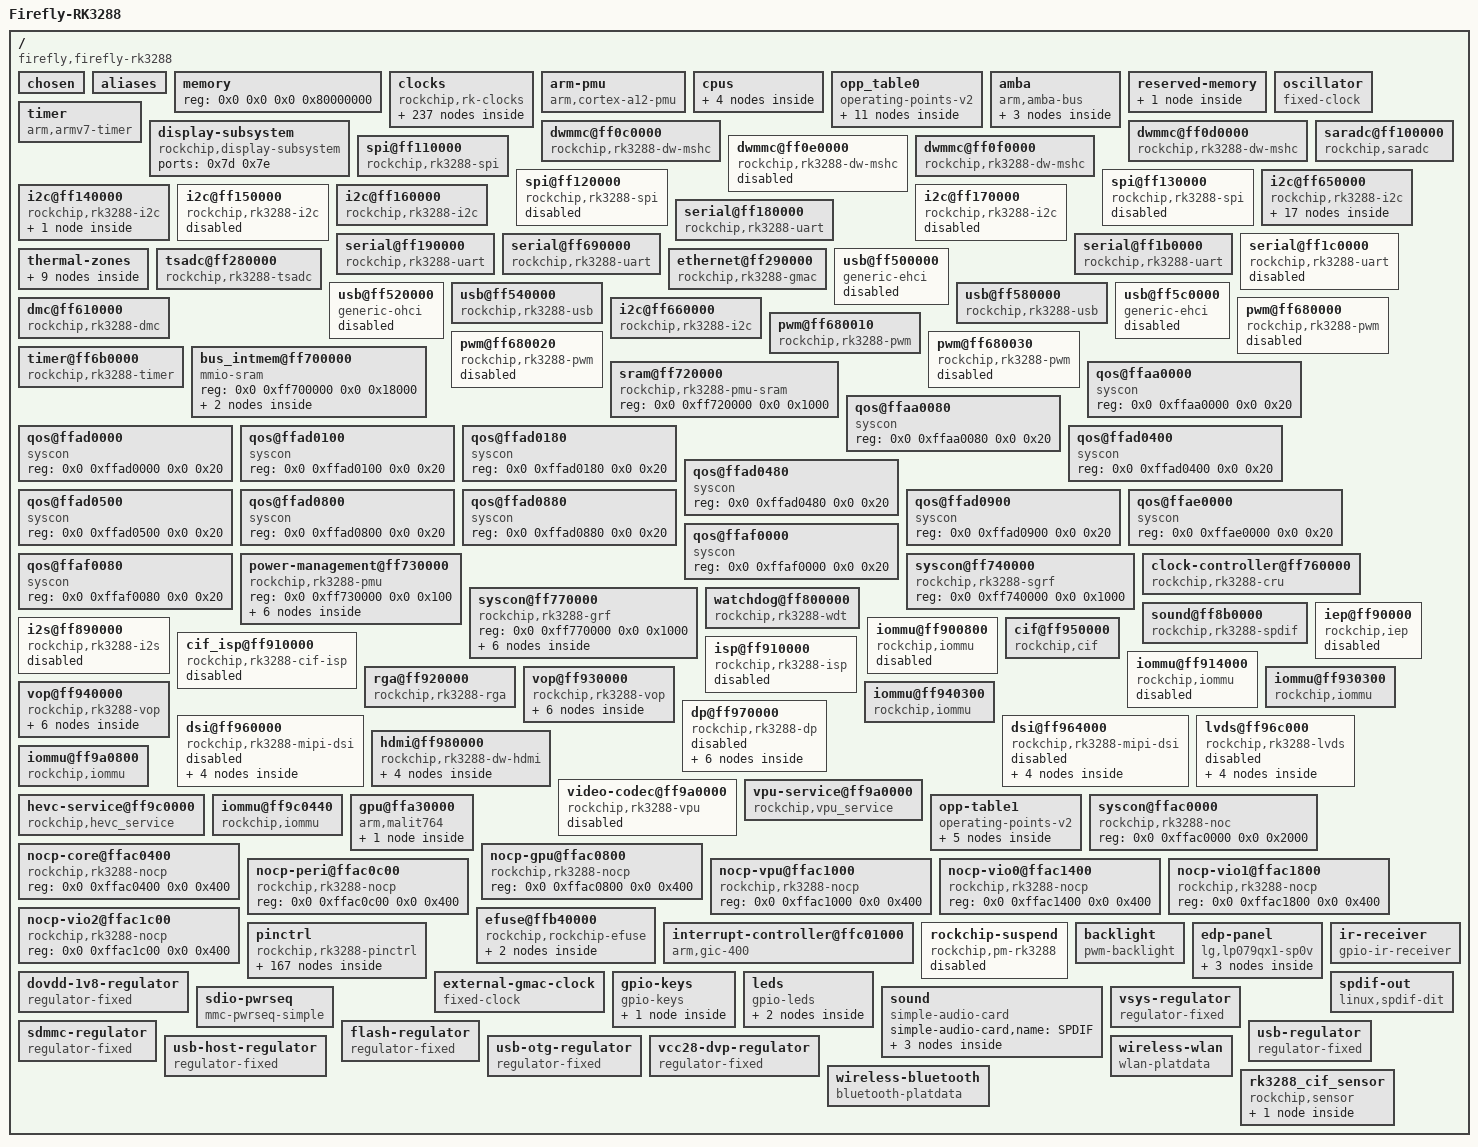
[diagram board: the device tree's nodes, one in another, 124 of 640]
/dts-v1/;

/ {
	#address-cells = <0x2>;
	#size-cells = <0x2>;
	compatible = "firefly,firefly-rk3288", "rockchip,rk3288";
	interrupt-parent = <0x1>;
	model = "Firefly-RK3288";

	chosen {
	};

	aliases {
		ethernet0 = "/ethernet@ff290000";
		i2c0 = "/i2c@ff650000";
		i2c1 = "/i2c@ff140000";
		i2c2 = "/i2c@ff660000";
		i2c3 = "/i2c@ff150000";
		i2c4 = "/i2c@ff160000";
		i2c5 = "/i2c@ff170000";
		mshc0 = "/dwmmc@ff0f0000";
		mshc1 = "/dwmmc@ff0c0000";
		mshc2 = "/dwmmc@ff0d0000";
		mshc3 = "/dwmmc@ff0e0000";
		serial0 = "/serial@ff180000";
		serial1 = "/serial@ff190000";
		serial2 = "/serial@ff690000";
		serial3 = "/serial@ff1b0000";
		serial4 = "/serial@ff1c0000";
		spi0 = "/spi@ff110000";
		spi1 = "/spi@ff120000";
		spi2 = "/spi@ff130000";
		dsi0 = "/dsi@ff960000";
		dsi1 = "/dsi@ff964000";
	};

	memory {
		device_type = "memory";
		reg = <0x0 0x0 0x0 0x80000000>;
	};

	clocks {
		compatible = "rockchip,rk-clocks";
		#address-cells = <0x1>;
		#size-cells = <0x1>;
		ranges = <0x0 0xff760000 0x1b0>;

		fixed_rate_cons {
			compatible = "rockchip,rk-fixed-rate-cons";

			xin12m {
				compatible = "rockchip,rk-fixed-clock";
				clocks = <0x2>;
				clock-output-names = "xin12m";
				clock-frequency = <0xb71b00>;
				#clock-cells = <0x0>;
				linux,phandle = <0x19>;
				phandle = <0x19>;
			};

			xin32k {
				compatible = "rockchip,rk-fixed-clock";
				clock-output-names = "xin32k";
				clock-frequency = <0x7d00>;
				#clock-cells = <0x0>;
				linux,phandle = <0x11>;
				phandle = <0x11>;
			};

			io_27m_in {
				compatible = "rockchip,rk-fixed-clock";
				clock-output-names = "io_27m_in";
				clock-frequency = <0x19bfcc0>;
				#clock-cells = <0x0>;
				linux,phandle = <0x4e>;
				phandle = <0x4e>;
			};

			dummy {
				compatible = "rockchip,rk-fixed-clock";
				clock-output-names = "dummy";
				clock-frequency = <0x0>;
				#clock-cells = <0x0>;
				linux,phandle = <0x12>;
				phandle = <0x12>;
			};

			dummy_cpll {
				compatible = "rockchip,rk-fixed-clock";
				clock-output-names = "dummy_cpll";
				clock-frequency = <0x0>;
				#clock-cells = <0x0>;
				linux,phandle = <0xf>;
				phandle = <0xf>;
			};

			i2s_clkin {
				compatible = "rockchip,rk-fixed-clock";
				clock-output-names = "i2s_clkin";
				clock-frequency = <0x0>;
				#clock-cells = <0x0>;
				linux,phandle = <0x18>;
				phandle = <0x18>;
			};

			edp_24m_clkin {
				compatible = "rockchip,rk-fixed-clock";
				#clock-cells = <0x0>;
				clock-output-names = "edp_24m_clkin";
				clock-frequency = <0x0>;
				linux,phandle = <0x41>;
				phandle = <0x41>;
			};

			gmac_clkin {
				compatible = "rockchip,rk-fixed-clock";
				#clock-cells = <0x0>;
				clock-output-names = "gmac_clkin";
				clock-frequency = <0x7735940>;
				linux,phandle = <0x33>;
				phandle = <0x33>;
			};

			clk_hsadc_ext {
				compatible = "rockchip,rk-fixed-clock";
				#clock-cells = <0x0>;
				clock-output-names = "clk_hsadc_ext";
				clock-frequency = <0x0>;
				linux,phandle = <0x35>;
				phandle = <0x35>;
			};

			jtag_clkin {
				compatible = "rockchip,rk-fixed-clock";
				#clock-cells = <0x0>;
				clock-output-names = "jtag_clkin";
				clock-frequency = <0x0>;
				linux,phandle = <0x61>;
				phandle = <0x61>;
			};

			pclkin_cif {
				compatible = "rockchip,rk-fixed-clock";
				#clock-cells = <0x0>;
				clock-output-names = "pclkin_cif";
				clock-frequency = <0x0>;
				linux,phandle = <0x72>;
				phandle = <0x72>;
			};

			pclkin_isp {
				compatible = "rockchip,rk-fixed-clock";
				#clock-cells = <0x0>;
				clock-output-names = "pclkin_isp";
				clock-frequency = <0x0>;
				linux,phandle = <0x73>;
				phandle = <0x73>;
			};

			hsadc_0_tsp {
				compatible = "rockchip,rk-fixed-clock";
				#clock-cells = <0x0>;
				clock-output-names = "hsadc_0_tsp";
				clock-frequency = <0x0>;
				linux,phandle = <0x65>;
				phandle = <0x65>;
			};

			hsadc_1_tsp {
				compatible = "rockchip,rk-fixed-clock";
				#clock-cells = <0x0>;
				clock-output-names = "hsadc_1_tsp";
				clock-frequency = <0x0>;
				linux,phandle = <0x66>;
				phandle = <0x66>;
			};
		};

		fixed_factor_cons {
			compatible = "rockchip,rk-fixed-factor-cons";

			otgphy0_480m {
				compatible = "rockchip,rk-fixed-factor-clock";
				clocks = <0x3 0x4>;
				clock-output-names = "otgphy0_480m";
				clock-div = <0x1>;
				clock-mult = <0x14>;
				#clock-cells = <0x0>;
				linux,phandle = <0x2a>;
				phandle = <0x2a>;
			};

			otgphy1_480m {
				compatible = "rockchip,rk-fixed-factor-clock";
				clocks = <0x3 0x5>;
				clock-output-names = "otgphy1_480m";
				clock-div = <0x1>;
				clock-mult = <0x14>;
				#clock-cells = <0x0>;
				linux,phandle = <0x28>;
				phandle = <0x28>;
			};

			otgphy2_480m {
				compatible = "rockchip,rk-fixed-factor-clock";
				clocks = <0x3 0x6>;
				clock-output-names = "otgphy2_480m";
				clock-div = <0x1>;
				clock-mult = <0x14>;
				#clock-cells = <0x0>;
				linux,phandle = <0x29>;
				phandle = <0x29>;
			};

			clk_hsadc_inv {
				compatible = "rockchip,rk-fixed-factor-clock";
				clocks = <0x4>;
				clock-output-names = "clk_hsadc_inv";
				clock-div = <0x1>;
				clock-mult = <0x1>;
				#clock-cells = <0x0>;
				linux,phandle = <0x36>;
				phandle = <0x36>;
			};

			pclkin_cif_inv {
				compatible = "rockchip,rk-fixed-factor-clock";
				clocks = <0x5 0x0>;
				clock-output-names = "pclkin_cif_inv";
				clock-div = <0x1>;
				clock-mult = <0x1>;
				#clock-cells = <0x0>;
				linux,phandle = <0x44>;
				phandle = <0x44>;
			};

			pclkin_isp_inv {
				compatible = "rockchip,rk-fixed-factor-clock";
				clocks = <0x5 0x3>;
				clock-output-names = "pclkin_isp_inv";
				clock-div = <0x1>;
				clock-mult = <0x1>;
				#clock-cells = <0x0>;
				linux,phandle = <0x43>;
				phandle = <0x43>;
			};

			hclk_vepu {
				compatible = "rockchip,rk-fixed-factor-clock";
				clocks = <0x6>;
				clock-output-names = "hclk_vepu";
				clock-div = <0x4>;
				clock-mult = <0x1>;
				#clock-cells = <0x0>;
			};

			hclk_vdpu {
				compatible = "rockchip,rk-fixed-factor-clock";
				clocks = <0x7>;
				clock-output-names = "hclk_vdpu";
				clock-div = <0x4>;
				clock-mult = <0x1>;
				#clock-cells = <0x0>;
			};
		};

		pd_cons {
			compatible = "rockchip,rk-pd-cons";

			pd_gpu {
				compatible = "rockchip,rk-pd-clock";
				clock-output-names = "pd_gpu";
				rockchip,pd-id = <0x8>;
				#clock-cells = <0x0>;
			};

			pd_video {
				compatible = "rockchip,rk-pd-clock";
				clock-output-names = "pd_video";
				rockchip,pd-id = <0xc>;
				#clock-cells = <0x0>;
			};

			pd_vio {
				compatible = "rockchip,rk-pd-clock";
				clock-output-names = "pd_vio";
				rockchip,pd-id = <0xd>;
				#clock-cells = <0x0>;
				linux,phandle = <0x8>;
				phandle = <0x8>;
			};

			pd_hevc {
				compatible = "rockchip,rk-pd-clock";
				clock-output-names = "pd_hevc";
				rockchip,pd-id = <0x9>;
				#clock-cells = <0x0>;
			};

			pd_edp {
				compatible = "rockchip,rk-pd-clock";
				clocks = <0x8>;
				clock-output-names = "pd_edp";
				rockchip,pd-id = <0xff>;
				#clock-cells = <0x0>;
			};

			pd_vop0 {
				compatible = "rockchip,rk-pd-clock";
				clocks = <0x8>;
				clock-output-names = "pd_vop0";
				rockchip,pd-id = <0xff>;
				#clock-cells = <0x0>;
			};

			pd_vop1 {
				compatible = "rockchip,rk-pd-clock";
				clocks = <0x8>;
				clock-output-names = "pd_vop1";
				rockchip,pd-id = <0xff>;
				#clock-cells = <0x0>;
			};

			pd_isp {
				compatible = "rockchip,rk-pd-clock";
				clocks = <0x8>;
				clock-output-names = "pd_isp";
				rockchip,pd-id = <0xff>;
				#clock-cells = <0x0>;
				linux,phandle = <0xdf>;
				phandle = <0xdf>;
			};

			pd_iep {
				compatible = "rockchip,rk-pd-clock";
				clocks = <0x8>;
				clock-output-names = "pd_iep";
				rockchip,pd-id = <0xff>;
				#clock-cells = <0x0>;
			};

			pd_rga {
				compatible = "rockchip,rk-pd-clock";
				clocks = <0x8>;
				clock-output-names = "pd_rga";
				rockchip,pd-id = <0xff>;
				#clock-cells = <0x0>;
			};

			pd_mipicsi {
				compatible = "rockchip,rk-pd-clock";
				clocks = <0x8>;
				clock-output-names = "pd_mipicsi";
				rockchip,pd-id = <0xff>;
				#clock-cells = <0x0>;
			};

			pd_mipidsi {
				compatible = "rockchip,rk-pd-clock";
				clocks = <0x8>;
				clock-output-names = "pd_mipidsi";
				rockchip,pd-id = <0xff>;
				#clock-cells = <0x0>;
			};

			pd_lvds {
				compatible = "rockchip,rk-pd-clock";
				clocks = <0x8>;
				clock-output-names = "pd_lvds";
				rockchip,pd-id = <0xff>;
				#clock-cells = <0x0>;
			};

			pd_hdmi {
				compatible = "rockchip,rk-pd-clock";
				clocks = <0x8>;
				clock-output-names = "pd_hdmi";
				rockchip,pd-id = <0xff>;
				#clock-cells = <0x0>;
			};
		};

		clock_regs {
			compatible = "rockchip,rk-clock-regs";
			#address-cells = <0x1>;
			#size-cells = <0x1>;
			reg = <0x0 0x3ff>;
			ranges;

			pll_cons {
				compatible = "rockchip,rk-pll-cons";
				#address-cells = <0x1>;
				#size-cells = <0x1>;
				ranges;

				pll-clk@0000 {
					compatible = "rockchip,rk3188-pll-clk";
					reg = <0x0 0x10>;
					mode-reg = <0x50 0x0>;
					status-reg = <0x284 0x6>;
					clocks = <0x2>;
					clock-output-names = "clk_apll";
					rockchip,pll-type = <0x10>;
					#clock-cells = <0x0>;
					linux,phandle = <0xa>;
					phandle = <0xa>;
				};

				pll-clk@0010 {
					compatible = "rockchip,rk3188-pll-clk";
					reg = <0x10 0x10>;
					mode-reg = <0x50 0x4>;
					status-reg = <0x284 0x5>;
					clocks = <0x2>;
					clock-output-names = "clk_dpll";
					rockchip,pll-type = <0x4>;
					#clock-cells = <0x0>;
					linux,phandle = <0x3a>;
					phandle = <0x3a>;
				};

				pll-clk@0020 {
					compatible = "rockchip,rk3188-pll-clk";
					reg = <0x20 0x10>;
					mode-reg = <0x50 0x8>;
					status-reg = <0x284 0x7>;
					clocks = <0x2>;
					clock-output-names = "clk_cpll";
					rockchip,pll-type = <0x20>;
					#clock-cells = <0x0>;
					#clock-init-cells = <0x1>;
					linux,phandle = <0x3d>;
					phandle = <0x3d>;
				};

				pll-clk@0030 {
					compatible = "rockchip,rk3188-pll-clk";
					reg = <0x30 0x10>;
					mode-reg = <0x50 0xc>;
					status-reg = <0x284 0x8>;
					clocks = <0x2>;
					clock-output-names = "clk_gpll";
					rockchip,pll-type = <0x4>;
					#clock-cells = <0x0>;
					#clock-init-cells = <0x1>;
					linux,phandle = <0x10>;
					phandle = <0x10>;
				};

				pll-clk@0040 {
					compatible = "rockchip,rk3188-pll-clk";
					reg = <0x40 0x10>;
					mode-reg = <0x50 0xe>;
					status-reg = <0x284 0x9>;
					clocks = <0x2>;
					clock-output-names = "clk_npll";
					rockchip,pll-type = <0x4>;
					#clock-cells = <0x0>;
					#clock-init-cells = <0x1>;
					linux,phandle = <0x1f>;
					phandle = <0x1f>;
				};
			};

			clk_sel_cons {
				compatible = "rockchip,rk-sel-cons";
				#address-cells = <0x1>;
				#size-cells = <0x1>;
				ranges;

				sel-con@0060 {
					compatible = "rockchip,rk3188-selcon";
					reg = <0x60 0x4>;
					#address-cells = <0x1>;
					#size-cells = <0x1>;

					aclk_core_m0_div {
						compatible = "rockchip,rk3188-div-con";
						rockchip,bits = <0x0 0x4>;
						clocks = <0x9>;
						clock-output-names = "aclk_core_m0";
						rockchip,div-type = <0x0>;
						#clock-cells = <0x0>;
						rockchip,clkops-idx = <0xc>;
						linux,phandle = <0x6c>;
						phandle = <0x6c>;
					};

					aclk_core_mp_div {
						compatible = "rockchip,rk3188-div-con";
						rockchip,bits = <0x4 0x4>;
						clocks = <0x9>;
						clock-output-names = "aclk_core_mp";
						rockchip,div-type = <0x0>;
						#clock-cells = <0x0>;
						rockchip,clkops-idx = <0xc>;
						linux,phandle = <0x6d>;
						phandle = <0x6d>;
					};

					clk_core_div {
						compatible = "rockchip,rk3188-div-con";
						rockchip,bits = <0x8 0x5>;
						clocks = <0x9>;
						clock-output-names = "clk_core";
						rockchip,div-type = <0x0>;
						#clock-cells = <0x0>;
						rockchip,clkops-idx = <0xb>;
						rockchip,flags = <0xc0>;
					};

					clk_core_mux {
						compatible = "rockchip,rk3188-mux-con";
						rockchip,bits = <0xf 0x1>;
						clocks = <0xa 0xb 0x2>;
						clock-output-names = "clk_core";
						#clock-cells = <0x0>;
						#clock-init-cells = <0x1>;
						linux,phandle = <0x9>;
						phandle = <0x9>;
					};
				};

				sel-con@0064 {
					compatible = "rockchip,rk3188-selcon";
					reg = <0x64 0x4>;
					#address-cells = <0x1>;
					#size-cells = <0x1>;

					aclk_bus_div {
						compatible = "rockchip,rk3188-div-con";
						rockchip,bits = <0x0 0x3>;
						clocks = <0xc>;
						clock-output-names = "aclk_bus";
						rockchip,div-type = <0x0>;
						#clock-cells = <0x0>;
						#clock-init-cells = <0x1>;
						linux,phandle = <0xe>;
						phandle = <0xe>;
					};

					aclk_bus_src_div {
						compatible = "rockchip,rk3188-div-con";
						rockchip,bits = <0x3 0x5>;
						clocks = <0xd>;
						clock-output-names = "aclk_bus_src";
						rockchip,div-type = <0x0>;
						#clock-cells = <0x0>;
						rockchip,clkops-idx = <0x1>;
						rockchip,flags = <0x80>;
						linux,phandle = <0xc>;
						phandle = <0xc>;
					};

					hclk_bus_div {
						compatible = "rockchip,rk3188-div-con";
						rockchip,bits = <0x8 0x2>;
						clocks = <0xe>;
						clock-output-names = "hclk_bus";
						rockchip,div-type = <0x80>;
						rockchip,div-relations = <0x0 0x1 0x1 0x2 0x3 0x4>;
						#clock-cells = <0x0>;
						#clock-init-cells = <0x1>;
						linux,phandle = <0x57>;
						phandle = <0x57>;
					};

					pclk_bus_div {
						compatible = "rockchip,rk3188-div-con";
						rockchip,bits = <0xc 0x3>;
						clocks = <0xe>;
						clock-output-names = "pclk_bus";
						rockchip,div-type = <0x0>;
						#clock-cells = <0x0>;
						#clock-init-cells = <0x1>;
						linux,phandle = <0x58>;
						phandle = <0x58>;
					};

					aclk_bus_src_mux {
						compatible = "rockchip,rk3188-mux-con";
						rockchip,bits = <0xf 0x1>;
						clocks = <0xf 0x10>;
						clock-output-names = "aclk_bus_src";
						#clock-cells = <0x0>;
						#clock-init-cells = <0x1>;
						linux,phandle = <0xd>;
						phandle = <0xd>;
					};
				};

				sel-con@0068 {
					compatible = "rockchip,rk3188-selcon";
					reg = <0x68 0x4>;
					#address-cells = <0x1>;
					#size-cells = <0x1>;

					clk_tsadc_div {
						compatible = "rockchip,rk3188-div-con";
						rockchip,bits = <0x0 0x6>;
						clocks = <0x11>;
						clock-output-names = "clk_tsadc";
						rockchip,div-type = <0x0>;
						#clock-cells = <0x0>;
						linux,phandle = <0x5b>;
						phandle = <0x5b>;
					};

					testout_div {
						compatible = "rockchip,rk3188-div-con";
						rockchip,bits = <0x8 0x5>;
						clocks = <0x12>;
						clock-output-names = "testout_div";
						rockchip,div-type = <0x0>;
						#clock-cells = <0x0>;
					};
				};

				sel-con@006c {
					compatible = "rockchip,rk3188-selcon";
					reg = <0x6c 0x4>;
					#address-cells = <0x1>;
					#size-cells = <0x1>;

					clk_uart4_div {
						compatible = "rockchip,rk3188-div-con";
						rockchip,bits = <0x0 0x7>;
						clocks = <0x13>;
						clock-output-names = "clk_uart4_div";
						rockchip,div-type = <0x0>;
						#clock-cells = <0x0>;
						linux,phandle = <0x14>;
						phandle = <0x14>;
					};

					uart4_mux {
						compatible = "rockchip,rk3188-mux-con";
						rockchip,bits = <0x8 0x2>;
						clocks = <0x14 0x15 0x2 0x12>;
						clock-output-names = "clk_uart4";
						#clock-cells = <0x0>;
						rockchip,clkops-idx = <0xe>;
						rockchip,flags = <0x4>;
					};
				};

				sel-con@0070 {
					compatible = "rockchip,rk3188-selcon";
					reg = <0x70 0x4>;
					#address-cells = <0x1>;
					#size-cells = <0x1>;

					i2s_pll_div {
						compatible = "rockchip,rk3188-div-con";
						rockchip,bits = <0x0 0x7>;
						clocks = <0x16>;
						clock-output-names = "clk_i2s_pll";
						rockchip,div-type = <0x0>;
						#clock-cells = <0x0>;
						rockchip,clkops-idx = <0x1>;
						rockchip,flags = <0x80>;
					};

					i2s_mux {
						compatible = "rockchip,rk3188-mux-con";
						rockchip,bits = <0x8 0x2>;
						clocks = <0x16 0x17 0x18 0x19>;
						clock-output-names = "clk_i2s";
						#clock-cells = <0x0>;
						rockchip,clkops-idx = <0xe>;
						rockchip,flags = <0x4>;
						linux,phandle = <0x1a>;
						phandle = <0x1a>;
					};

					i2s_outclk_mux {
						compatible = "rockchip,rk3188-mux-con";
						rockchip,bits = <0xc 0x1>;
						clocks = <0x1a 0x19>;
						clock-output-names = "clk_i2s_out";
						#clock-cells = <0x0>;
						linux,phandle = <0x5e>;
						phandle = <0x5e>;
					};

					i2s_pll_mux {
						compatible = "rockchip,rk3188-mux-con";
						rockchip,bits = <0xf 0x1>;
						clocks = <0xf 0x10>;
						clock-output-names = "clk_i2s_pll";
						#clock-cells = <0x0>;
						#clock-init-cells = <0x1>;
						linux,phandle = <0x16>;
						phandle = <0x16>;
					};
				};

				sel-con@0074 {
					compatible = "rockchip,rk3188-selcon";
					reg = <0x74 0x4>;
					#address-cells = <0x1>;
					#size-cells = <0x1>;

					spdif_div {
						compatible = "rockchip,rk3188-div-con";
						rockchip,bits = <0x0 0x7>;
						clocks = <0x1b>;
						clock-output-names = "spdif_div";
						rockchip,div-type = <0x0>;
						#clock-cells = <0x0>;
						linux,phandle = <0x1c>;
						phandle = <0x1c>;
					};

					spdif_mux {
						compatible = "rockchip,rk3188-mux-con";
						rockchip,bits = <0x8 0x2>;
						clocks = <0x1c 0x1d 0x19 0x12>;
						clock-output-names = "clk_spdif";
						#clock-cells = <0x0>;
						rockchip,clkops-idx = <0xe>;
						rockchip,flags = <0x4>;
						linux,phandle = <0x5f>;
						phandle = <0x5f>;
					};

					spdif_pll_mux {
						compatible = "rockchip,rk3188-mux-con";
						rockchip,bits = <0xf 0x1>;
						clocks = <0xf 0x10>;
						clock-output-names = "clk_spdif_pll";
						#clock-cells = <0x0>;
						#clock-init-cells = <0x1>;
						linux,phandle = <0x1b>;
						phandle = <0x1b>;
					};
				};

				sel-con@0078 {
					compatible = "rockchip,rk3188-selcon";
					reg = <0x78 0x4>;
					#address-cells = <0x1>;
					#size-cells = <0x1>;

					clk_isp_div {
						compatible = "rockchip,rk3188-div-con";
						rockchip,bits = <0x0 0x6>;
						clocks = <0x1e>;
						clock-output-names = "clk_isp";
						rockchip,div-type = <0x0>;
						#clock-cells = <0x0>;
						rockchip,clkops-idx = <0x1>;
					};

					clk_isp_mux {
						compatible = "rockchip,rk3188-mux-con";
						rockchip,bits = <0x6 0x2>;
						clocks = <0xf 0x10 0x1f>;
						clock-output-names = "clk_isp";
						#clock-cells = <0x0>;
						#clock-init-cells = <0x1>;
						linux,phandle = <0x1e>;
						phandle = <0x1e>;
					};

					clk_isp_jpe_div {
						compatible = "rockchip,rk3188-div-con";
						rockchip,bits = <0x8 0x6>;
						clocks = <0x20>;
						clock-output-names = "clk_isp_jpe";
						rockchip,div-type = <0x0>;
						#clock-cells = <0x0>;
						rockchip,clkops-idx = <0x1>;
					};

					clk_isp_jpe_mux {
						compatible = "rockchip,rk3188-mux-con";
						rockchip,bits = <0xe 0x2>;
						clocks = <0xf 0x10 0x1f>;
						clock-output-names = "clk_isp_jpe";
						#clock-cells = <0x0>;
						#clock-init-cells = <0x1>;
						linux,phandle = <0x20>;
						phandle = <0x20>;
					};
				};

				sel-con@007c {
					compatible = "rockchip,rk3188-selcon";
					reg = <0x7c 0x4>;
					#address-cells = <0x1>;
					#size-cells = <0x1>;

					uart4_frac {
						compatible = "rockchip,rk3188-frac-con";
						clocks = <0x14>;
						clock-output-names = "uart4_frac";
						rockchip,bits = <0x0 0x20>;
						rockchip,clkops-idx = <0x5>;
						#clock-cells = <0x0>;
						linux,phandle = <0x15>;
						phandle = <0x15>;
					};
				};

				sel-con@0080 {
					compatible = "rockchip,rk3188-selcon";
					reg = <0x80 0x4>;
					#address-cells = <0x1>;
					#size-cells = <0x1>;

					i2s_frac {
						compatible = "rockchip,rk3188-frac-con";
						clocks = <0x16>;
						clock-output-names = "i2s_frac";
						rockchip,bits = <0x0 0x20>;
						rockchip,clkops-idx = <0x5>;
						#clock-cells = <0x0>;
						linux,phandle = <0x17>;
						phandle = <0x17>;
					};
				};

				sel-con@0084 {
					compatible = "rockchip,rk3188-selcon";
					reg = <0x84 0x4>;
					#address-cells = <0x1>;
					#size-cells = <0x1>;

					spdif_frac {
						compatible = "rockchip,rk3188-frac-con";
						clocks = <0x1c>;
						clock-output-names = "spdif_frac";
						rockchip,bits = <0x0 0x20>;
						rockchip,clkops-idx = <0x5>;
						#clock-cells = <0x0>;
						linux,phandle = <0x1d>;
						phandle = <0x1d>;
					};
				};

				sel-con@0088 {
					compatible = "rockchip,rk3188-selcon";
					reg = <0x88 0x4>;
					#address-cells = <0x1>;
					#size-cells = <0x1>;

					aclk_peri_div {
						compatible = "rockchip,rk3188-div-con";
						rockchip,bits = <0x0 0x5>;
						clocks = <0x21>;
						clock-output-names = "aclk_peri";
						rockchip,div-type = <0x0>;
						#clock-cells = <0x0>;
						rockchip,clkops-idx = <0x1>;
						rockchip,flags = <0x80>;
					};

					hclk_peri_div {
						compatible = "rockchip,rk3188-div-con";
						rockchip,bits = <0x8 0x2>;
						clocks = <0x21>;
						clock-output-names = "hclk_peri";
						rockchip,div-type = <0x80>;
						rockchip,div-relations = <0x0 0x1 0x1 0x2 0x2 0x4>;
						#clock-cells = <0x0>;
						#clock-init-cells = <0x1>;
						linux,phandle = <0x59>;
						phandle = <0x59>;
					};

					pclk_peri_div {
						compatible = "rockchip,rk3188-div-con";
						rockchip,bits = <0xc 0x2>;
						clocks = <0x21>;
						clock-output-names = "pclk_peri";
						rockchip,div-type = <0x80>;
						rockchip,div-relations = <0x0 0x1 0x1 0x2 0x2 0x4 0x3 0x8>;
						#clock-cells = <0x0>;
						#clock-init-cells = <0x1>;
						linux,phandle = <0x5a>;
						phandle = <0x5a>;
					};

					aclk_peri_mux {
						compatible = "rockchip,rk3188-mux-con";
						rockchip,bits = <0xf 0x1>;
						clocks = <0xf 0x10>;
						clock-output-names = "aclk_peri";
						#clock-cells = <0x0>;
						#clock-init-cells = <0x1>;
						linux,phandle = <0x21>;
						phandle = <0x21>;
					};
				};

				sel-con@008c {
					compatible = "rockchip,rk3188-selcon";
					reg = <0x8c 0x4>;
					#address-cells = <0x1>;
					#size-cells = <0x1>;

					clk_sdmmc_div {
						compatible = "rockchip,rk3188-div-con";
						rockchip,bits = <0x0 0x6>;
						clocks = <0x22>;
						clock-output-names = "clk_sdmmc";
						rockchip,div-type = <0x0>;
						#clock-cells = <0x0>;
						rockchip,clkops-idx = <0x3>;
					};

					clk_sdmmc_mux {
						compatible = "rockchip,rk3188-mux-con";
						rockchip,bits = <0x6 0x2>;
						clocks = <0xf 0x10 0x2>;
						clock-output-names = "clk_sdmmc";
						#clock-cells = <0x0>;
						linux,phandle = <0x22>;
						phandle = <0x22>;
					};

					ehci1phy_12m_div {
						compatible = "rockchip,rk3188-div-con";
						rockchip,bits = <0x8 0x6>;
						clocks = <0x23>;
						clock-output-names = "ehci1phy_12m_div";
						rockchip,div-type = <0x0>;
						#clock-cells = <0x0>;
						linux,phandle = <0x42>;
						phandle = <0x42>;
					};
				};

				sel-con@0090 {
					compatible = "rockchip,rk3188-selcon";
					reg = <0x90 0x4>;
					#address-cells = <0x1>;
					#size-cells = <0x1>;

					clk_sdio0_div {
						compatible = "rockchip,rk3188-div-con";
						rockchip,bits = <0x0 0x6>;
						clocks = <0x24>;
						clock-output-names = "clk_sdio0";
						rockchip,div-type = <0x0>;
						#clock-cells = <0x0>;
						rockchip,clkops-idx = <0x3>;
					};

					clk_sdio0_mux {
						compatible = "rockchip,rk3188-mux-con";
						rockchip,bits = <0x6 0x2>;
						clocks = <0xf 0x10 0x2>;
						clock-output-names = "clk_sdio0";
						#clock-cells = <0x0>;
						linux,phandle = <0x24>;
						phandle = <0x24>;
					};

					clk_emmc_div {
						compatible = "rockchip,rk3188-div-con";
						rockchip,bits = <0x8 0x6>;
						clocks = <0x25>;
						clock-output-names = "clk_emmc";
						rockchip,div-type = <0x0>;
						#clock-cells = <0x0>;
						rockchip,clkops-idx = <0x3>;
					};

					clk_emmc_mux {
						compatible = "rockchip,rk3188-mux-con";
						rockchip,bits = <0xe 0x2>;
						clocks = <0xf 0x10 0x2>;
						clock-output-names = "clk_emmc";
						#clock-cells = <0x0>;
						linux,phandle = <0x25>;
						phandle = <0x25>;
					};
				};

				sel-con@0094 {
					compatible = "rockchip,rk3188-selcon";
					reg = <0x94 0x4>;
					#address-cells = <0x1>;
					#size-cells = <0x1>;

					clk_uart0_pll_div {
						compatible = "rockchip,rk3188-div-con";
						rockchip,bits = <0x0 0x7>;
						clocks = <0x26>;
						clock-output-names = "clk_uart0_pll";
						rockchip,div-type = <0x0>;
						#clock-cells = <0x0>;
						rockchip,clkops-idx = <0x1>;
					};

					uart0_mux {
						compatible = "rockchip,rk3188-mux-con";
						rockchip,bits = <0x8 0x2>;
						clocks = <0x26 0x27 0x2 0x12>;
						clock-output-names = "clk_uart0";
						#clock-cells = <0x0>;
						rockchip,clkops-idx = <0xe>;
						rockchip,flags = <0x4>;
					};

					usbphy_480m_mux {
						compatible = "rockchip,rk3188-mux-con";
						rockchip,bits = <0xb 0x2>;
						clocks = <0x28 0x29 0x2a>;
						clock-output-names = "usbphy_480m";
						#clock-cells = <0x0>;
						rockchip,clkops-idx = <0xf>;
						#clock-init-cells = <0x1>;
						linux,phandle = <0x2b>;
						phandle = <0x2b>;
					};

					clk_uart0_pll_mux {
						compatible = "rockchip,rk3188-mux-con";
						rockchip,bits = <0xd 0x2>;
						clocks = <0xf 0x10 0x2b 0x1f>;
						clock-output-names = "clk_uart0_pll";
						#clock-cells = <0x0>;
						linux,phandle = <0x26>;
						phandle = <0x26>;
					};

					uart_pll_mux {
						compatible = "rockchip,rk3188-mux-con";
						rockchip,bits = <0xf 0x1>;
						clocks = <0xf 0x10>;
						clock-output-names = "uart_pll_mux";
						#clock-cells = <0x0>;
						#clock-init-cells = <0x1>;
						linux,phandle = <0x13>;
						phandle = <0x13>;
					};
				};

				sel-con@0098 {
					compatible = "rockchip,rk3188-selcon";
					reg = <0x98 0x4>;
					#address-cells = <0x1>;
					#size-cells = <0x1>;

					clk_uart1_div {
						compatible = "rockchip,rk3188-div-con";
						rockchip,bits = <0x0 0x7>;
						clocks = <0x13>;
						clock-output-names = "clk_uart1_div";
						rockchip,div-type = <0x0>;
						#clock-cells = <0x0>;
						linux,phandle = <0x2c>;
						phandle = <0x2c>;
					};

					uart1_mux {
						compatible = "rockchip,rk3188-mux-con";
						rockchip,bits = <0x8 0x2>;
						clocks = <0x2c 0x2d 0x2 0x12>;
						clock-output-names = "clk_uart1";
						#clock-cells = <0x0>;
						rockchip,clkops-idx = <0xe>;
						rockchip,flags = <0x4>;
					};
				};

				sel-con@009c {
					compatible = "rockchip,rk3188-selcon";
					reg = <0x9c 0x4>;
					#address-cells = <0x1>;
					#size-cells = <0x1>;

					clk_uart2_div {
						compatible = "rockchip,rk3188-div-con";
						rockchip,bits = <0x0 0x7>;
						clocks = <0x13>;
						clock-output-names = "clk_uart2_div";
						rockchip,div-type = <0x0>;
						#clock-cells = <0x0>;
						linux,phandle = <0x2e>;
						phandle = <0x2e>;
					};

					uart2_mux {
						compatible = "rockchip,rk3188-mux-con";
						rockchip,bits = <0x8 0x2>;
						clocks = <0x2e 0x2f 0x2 0x12>;
						clock-output-names = "clk_uart2";
						#clock-cells = <0x0>;
						rockchip,clkops-idx = <0xe>;
						rockchip,flags = <0x4>;
					};
				};

				sel-con@00a0 {
					compatible = "rockchip,rk3188-selcon";
					reg = <0xa0 0x4>;
					#address-cells = <0x1>;
					#size-cells = <0x1>;

					clk_uart3_div {
						compatible = "rockchip,rk3188-div-con";
						rockchip,bits = <0x0 0x7>;
						clocks = <0x13>;
						clock-output-names = "clk_uart3_div";
						rockchip,div-type = <0x0>;
						#clock-cells = <0x0>;
						linux,phandle = <0x30>;
						phandle = <0x30>;
					};

					uart3_mux {
						compatible = "rockchip,rk3188-mux-con";
						rockchip,bits = <0x8 0x2>;
						clocks = <0x30 0x31 0x2 0x12>;
						clock-output-names = "clk_uart3";
						#clock-cells = <0x0>;
						rockchip,clkops-idx = <0xe>;
						rockchip,flags = <0x4>;
					};
				};

				sel-con@00a4 {
					compatible = "rockchip,rk3188-selcon";
					reg = <0xa4 0x4>;
					#address-cells = <0x1>;
					#size-cells = <0x1>;

					uart0_frac {
						compatible = "rockchip,rk3188-frac-con";
						clocks = <0x26>;
						clock-output-names = "uart0_frac";
						rockchip,bits = <0x0 0x20>;
						rockchip,clkops-idx = <0x5>;
						#clock-cells = <0x0>;
						linux,phandle = <0x27>;
						phandle = <0x27>;
					};
				};

				sel-con@00a8 {
					compatible = "rockchip,rk3188-selcon";
					reg = <0xa8 0x4>;
					#address-cells = <0x1>;
					#size-cells = <0x1>;

					uart1_frac {
						compatible = "rockchip,rk3188-frac-con";
						clocks = <0x2c>;
						clock-output-names = "uart1_frac";
						rockchip,bits = <0x0 0x20>;
						rockchip,clkops-idx = <0x5>;
						#clock-cells = <0x0>;
						linux,phandle = <0x2d>;
						phandle = <0x2d>;
					};
				};

				sel-con@00ac {
					compatible = "rockchip,rk3188-selcon";
					reg = <0xac 0x4>;
					#address-cells = <0x1>;
					#size-cells = <0x1>;

					uart2_frac {
						compatible = "rockchip,rk3188-frac-con";
						clocks = <0x2e>;
						clock-output-names = "uart2_frac";
						rockchip,bits = <0x0 0x20>;
						rockchip,clkops-idx = <0x5>;
						#clock-cells = <0x0>;
						linux,phandle = <0x2f>;
						phandle = <0x2f>;
					};
				};

				sel-con@00b0 {
					compatible = "rockchip,rk3188-selcon";
					reg = <0xb0 0x4>;
					#address-cells = <0x1>;
					#size-cells = <0x1>;

					uart3_frac {
						compatible = "rockchip,rk3188-frac-con";
						clocks = <0x30>;
						clock-output-names = "uart3_frac";
						rockchip,bits = <0x0 0x20>;
						rockchip,clkops-idx = <0x5>;
						#clock-cells = <0x0>;
						linux,phandle = <0x31>;
						phandle = <0x31>;
					};
				};

				sel-con@00b4 {
					compatible = "rockchip,rk3188-selcon";
					reg = <0xb4 0x4>;
					#address-cells = <0x1>;
					#size-cells = <0x1>;

					clk_mac_pll_mux {
						compatible = "rockchip,rk3188-mux-con";
						rockchip,bits = <0x0 0x2>;
						clocks = <0x1f 0xf 0x10>;
						clock-output-names = "clk_mac_pll";
						#clock-cells = <0x0>;
						linux,phandle = <0x32>;
						phandle = <0x32>;
					};

					clk_mac_mux {
						compatible = "rockchip,rk3188-mux-con";
						rockchip,bits = <0x4 0x1>;
						clocks = <0x32 0x33>;
						clock-output-names = "clk_mac";
						#clock-cells = <0x0>;
						rockchip,clkops-idx = <0xa>;
						rockchip,flags = <0x4>;
						#clock-init-cells = <0x1>;
						linux,phandle = <0x62>;
						phandle = <0x62>;
					};

					clk_mac_pll_div {
						compatible = "rockchip,rk3188-div-con";
						rockchip,bits = <0x8 0x5>;
						clocks = <0x32>;
						clock-output-names = "clk_mac_pll";
						rockchip,div-type = <0x0>;
						#clock-cells = <0x0>;
						rockchip,clkops-idx = <0x1>;
					};
				};

				sel-con@00b8 {
					compatible = "rockchip,rk3188-selcon";
					reg = <0xb8 0x4>;
					#address-cells = <0x1>;
					#size-cells = <0x1>;

					clk_hsadc_pll_mux {
						compatible = "rockchip,rk3188-mux-con";
						rockchip,bits = <0x0 0x1>;
						clocks = <0xf 0x10>;
						clock-output-names = "clk_hsadc_pll";
						#clock-cells = <0x0>;
						linux,phandle = <0x34>;
						phandle = <0x34>;
					};

					clk_hsadc_out {
						compatible = "rockchip,rk3188-mux-con";
						rockchip,bits = <0x4 0x1>;
						clocks = <0x34 0x35>;
						clock-output-names = "clk_hsadc_out";
						#clock-cells = <0x0>;
						rockchip,clkops-idx = <0x9>;
						rockchip,flags = <0x4>;
						linux,phandle = <0x4>;
						phandle = <0x4>;
					};

					clk_hsadc {
						compatible = "rockchip,rk3188-mux-con";
						rockchip,bits = <0x7 0x1>;
						clocks = <0x4 0x36>;
						clock-output-names = "clk_hsadc";
						#clock-cells = <0x0>;
					};

					clk_hsadc_pll_div {
						compatible = "rockchip,rk3188-div-con";
						rockchip,bits = <0x8 0x8>;
						clocks = <0x34>;
						clock-output-names = "clk_hsadc_pll";
						rockchip,div-type = <0x0>;
						#clock-cells = <0x0>;
						rockchip,clkops-idx = <0x1>;
					};
				};

				sel-con@00c0 {
					compatible = "rockchip,rk3188-selcon";
					reg = <0xc0 0x4>;
					#address-cells = <0x1>;
					#size-cells = <0x1>;

					clk_saradc_div {
						compatible = "rockchip,rk3188-div-con";
						rockchip,bits = <0x8 0x8>;
						clocks = <0x2>;
						clock-output-names = "clk_saradc";
						rockchip,div-type = <0x0>;
						#clock-cells = <0x0>;
						linux,phandle = <0x5c>;
						phandle = <0x5c>;
					};
				};

				sel-con@00c4 {
					compatible = "rockchip,rk3188-selcon";
					reg = <0xc4 0x4>;
					#address-cells = <0x1>;
					#size-cells = <0x1>;

					clk_spi0_div {
						compatible = "rockchip,rk3188-div-con";
						rockchip,bits = <0x0 0x7>;
						clocks = <0x37>;
						clock-output-names = "clk_spi0";
						rockchip,div-type = <0x0>;
						#clock-cells = <0x0>;
						rockchip,clkops-idx = <0x1>;
					};

					clk_spi0_mux {
						compatible = "rockchip,rk3188-mux-con";
						rockchip,bits = <0x7 0x1>;
						clocks = <0xf 0x10>;
						clock-output-names = "clk_spi0";
						#clock-cells = <0x0>;
						linux,phandle = <0x37>;
						phandle = <0x37>;
					};

					clk_spi1_div {
						compatible = "rockchip,rk3188-div-con";
						rockchip,bits = <0x8 0x7>;
						clocks = <0x38>;
						clock-output-names = "clk_spi1";
						rockchip,div-type = <0x0>;
						#clock-cells = <0x0>;
						rockchip,clkops-idx = <0x1>;
					};

					clk_spi1_mux {
						compatible = "rockchip,rk3188-mux-con";
						rockchip,bits = <0xf 0x1>;
						clocks = <0xf 0x10>;
						clock-output-names = "clk_spi1";
						#clock-cells = <0x0>;
						linux,phandle = <0x38>;
						phandle = <0x38>;
					};
				};

				sel-con@00c8 {
					compatible = "rockchip,rk3188-selcon";
					reg = <0xc8 0x4>;
					#address-cells = <0x1>;
					#size-cells = <0x1>;

					ddr_div {
						compatible = "rockchip,rk3188-div-con";
						rockchip,bits = <0x0 0x2>;
						clocks = <0x39>;
						clock-output-names = "clk_ddr";
						rockchip,div-type = <0x80>;
						rockchip,div-relations = <0x0 0x1 0x1 0x2 0x3 0x4>;
						#clock-cells = <0x0>;
						rockchip,flags = <0xc0>;
						rockchip,clkops-idx = <0xd>;
					};

					ddr_clk_pll_mux {
						compatible = "rockchip,rk3188-mux-con";
						rockchip,bits = <0x2 0x1>;
						clocks = <0x3a 0x10>;
						clock-output-names = "clk_ddr";
						#clock-cells = <0x0>;
						linux,phandle = <0x39>;
						phandle = <0x39>;
					};

					crypto_div {
						compatible = "rockchip,rk3188-div-con";
						rockchip,bits = <0x6 0x2>;
						clocks = <0xe>;
						clock-output-names = "clk_crypto";
						rockchip,div-type = <0x0>;
						#clock-cells = <0x0>;
						#clock-init-cells = <0x1>;
						linux,phandle = <0x63>;
						phandle = <0x63>;
					};

					clk_cif_pll_mux {
						compatible = "rockchip,rk3188-mux-con";
						rockchip,bits = <0x8 0x1>;
						clocks = <0xf 0x10>;
						clock-output-names = "clk_cif_pll";
						#clock-cells = <0x0>;
						linux,phandle = <0x3c>;
						phandle = <0x3c>;
					};

					clk_cif_out_div {
						compatible = "rockchip,rk3188-div-con";
						rockchip,bits = <0x9 0x5>;
						clocks = <0x3b>;
						clock-output-names = "clk_cif_out";
						rockchip,div-type = <0x0>;
						#clock-cells = <0x0>;
						rockchip,clkops-idx = <0x1>;
					};

					clk_cif_out_mux {
						compatible = "rockchip,rk3188-mux-con";
						rockchip,bits = <0xf 0x1>;
						clocks = <0x3c 0x2>;
						clock-output-names = "clk_cif_out";
						#clock-cells = <0x0>;
						linux,phandle = <0x3b>;
						phandle = <0x3b>;
					};
				};

				sel-con@00cc {
					compatible = "rockchip,rk3188-selcon";
					reg = <0xcc 0x4>;
					#address-cells = <0x1>;
					#size-cells = <0x1>;

					dclk_lcdc0_mux {
						compatible = "rockchip,rk3188-mux-con";
						rockchip,bits = <0x0 0x2>;
						clocks = <0x3d 0x10 0x1f>;
						clock-output-names = "dclk_lcdc0";
						#clock-cells = <0x0>;
						linux,phandle = <0x3e>;
						phandle = <0x3e>;
					};

					dclk_lcdc0_div {
						compatible = "rockchip,rk3188-div-con";
						rockchip,bits = <0x8 0x8>;
						clocks = <0x3e>;
						clock-output-names = "dclk_lcdc0";
						rockchip,div-type = <0x0>;
						#clock-cells = <0x0>;
						rockchip,clkops-idx = <0x10>;
						rockchip,flags = <0x4>;
					};
				};

				sel-con@00d0 {
					compatible = "rockchip,rk3188-selcon";
					reg = <0xd0 0x4>;
					#address-cells = <0x1>;
					#size-cells = <0x1>;

					clk_edp_div {
						compatible = "rockchip,rk3188-div-con";
						rockchip,bits = <0x0 0x6>;
						clocks = <0x3f>;
						clock-output-names = "clk_edp";
						rockchip,div-type = <0x0>;
						#clock-cells = <0x0>;
						rockchip,clkops-idx = <0x1>;
					};

					clk_edp_mux {
						compatible = "rockchip,rk3188-mux-con";
						rockchip,bits = <0x6 0x2>;
						clocks = <0xf 0x10 0x1f>;
						clock-output-names = "clk_edp";
						#clock-cells = <0x0>;
						#clock-init-cells = <0x1>;
						linux,phandle = <0x3f>;
						phandle = <0x3f>;
					};

					hclk_vio_div {
						compatible = "rockchip,rk3188-div-con";
						rockchip,bits = <0x8 0x5>;
						clocks = <0x40 0xb>;
						clock-output-names = "hclk_vio";
						rockchip,div-type = <0x0>;
						#clock-cells = <0x0>;
						#clock-init-cells = <0x1>;
						linux,phandle = <0x71>;
						phandle = <0x71>;
					};

					edp_24m_mux {
						compatible = "rockchip,rk3188-mux-con";
						rockchip,bits = <0xf 0x1>;
						clocks = <0x41 0x2>;
						clock-output-names = "clk_edp_24m";
						#clock-cells = <0x0>;
						linux,phandle = <0x5d>;
						phandle = <0x5d>;
					};
				};

				sel-con@00d4 {
					compatible = "rockchip,rk3188-selcon";
					reg = <0xd4 0x4>;
					#address-cells = <0x1>;
					#size-cells = <0x1>;

					ehci1phy_480m_mux {
						compatible = "rockchip,rk3188-mux-con";
						rockchip,bits = <0x0 0x2>;
						clocks = <0xf 0x10 0x2b>;
						clock-output-names = "ehci1phy_480m";
						#clock-cells = <0x0>;
						linux,phandle = <0x23>;
						phandle = <0x23>;
					};

					ehci1phy_12m_mux {
						compatible = "rockchip,rk3188-mux-con";
						rockchip,bits = <0x2 0x1>;
						clocks = <0x3 0x9 0x42>;
						clock-output-names = "ehci1phy_12m";
						#clock-cells = <0x0>;
					};

					clkin_isp {
						compatible = "rockchip,rk3188-mux-con";
						rockchip,bits = <0x3 0x1>;
						clocks = <0x5 0x3 0x43>;
						clock-output-names = "clkin_isp";
						#clock-cells = <0x0>;
					};

					clkin_cif {
						compatible = "rockchip,rk3188-mux-con";
						rockchip,bits = <0x4 0x1>;
						clocks = <0x5 0x0 0x44>;
						clock-output-names = "clkin_cif";
						#clock-cells = <0x0>;
						linux,phandle = <0xe0>;
						phandle = <0xe0>;
					};

					dclk_lcdc1_mux {
						compatible = "rockchip,rk3188-mux-con";
						rockchip,bits = <0x6 0x2>;
						clocks = <0x3d 0x10 0x1f>;
						clock-output-names = "dclk_lcdc1";
						#clock-cells = <0x0>;
						linux,phandle = <0x45>;
						phandle = <0x45>;
					};

					dclk_lcdc1_div {
						compatible = "rockchip,rk3188-div-con";
						rockchip,bits = <0x8 0x8>;
						clocks = <0x45>;
						clock-output-names = "dclk_lcdc1";
						rockchip,div-type = <0x0>;
						#clock-cells = <0x0>;
						rockchip,clkops-idx = <0x11>;
						rockchip,flags = <0x4>;
					};
				};

				sel-con@00d8 {
					compatible = "rockchip,rk3188-selcon";
					reg = <0xd8 0x4>;
					#address-cells = <0x1>;
					#size-cells = <0x1>;

					aclk_rga_div {
						compatible = "rockchip,rk3188-div-con";
						rockchip,bits = <0x0 0x5>;
						clocks = <0x46>;
						clock-output-names = "aclk_rga";
						rockchip,div-type = <0x0>;
						#clock-cells = <0x0>;
						rockchip,clkops-idx = <0x1>;
					};

					aclk_rga_mux {
						compatible = "rockchip,rk3188-mux-con";
						rockchip,bits = <0x6 0x2>;
						clocks = <0xf 0x10 0x2b>;
						clock-output-names = "aclk_rga";
						#clock-cells = <0x0>;
						#clock-init-cells = <0x1>;
						linux,phandle = <0x46>;
						phandle = <0x46>;
					};

					clk_rga_div {
						compatible = "rockchip,rk3188-div-con";
						rockchip,bits = <0x8 0x5>;
						clocks = <0x47>;
						clock-output-names = "clk_rga";
						rockchip,div-type = <0x0>;
						#clock-cells = <0x0>;
						rockchip,clkops-idx = <0x1>;
					};

					clk_rga_mux {
						compatible = "rockchip,rk3188-mux-con";
						rockchip,bits = <0xe 0x2>;
						clocks = <0xf 0x10 0x2b>;
						clock-output-names = "clk_rga";
						#clock-cells = <0x0>;
						#clock-init-cells = <0x1>;
						linux,phandle = <0x47>;
						phandle = <0x47>;
					};
				};

				sel-con@00dc {
					compatible = "rockchip,rk3188-selcon";
					reg = <0xdc 0x4>;
					#address-cells = <0x1>;
					#size-cells = <0x1>;

					aclk_vio0_div {
						compatible = "rockchip,rk3188-div-con";
						rockchip,bits = <0x0 0x5>;
						clocks = <0x48>;
						clock-output-names = "aclk_vio0";
						rockchip,div-type = <0x0>;
						#clock-cells = <0x0>;
						rockchip,clkops-idx = <0x1>;
						rockchip,flags = <0x80>;
					};

					aclk_vio0_mux {
						compatible = "rockchip,rk3188-mux-con";
						rockchip,bits = <0x6 0x2>;
						clocks = <0x3d 0x10 0x2b>;
						clock-output-names = "aclk_vio0";
						#clock-cells = <0x0>;
						#clock-init-cells = <0x1>;
						linux,phandle = <0x48>;
						phandle = <0x48>;
					};

					aclk_vio1_div {
						compatible = "rockchip,rk3188-div-con";
						rockchip,bits = <0x8 0x5>;
						clocks = <0x49>;
						clock-output-names = "aclk_vio1";
						rockchip,div-type = <0x0>;
						#clock-cells = <0x0>;
						rockchip,clkops-idx = <0x1>;
						rockchip,flags = <0x80>;
					};

					aclk_vio1_mux {
						compatible = "rockchip,rk3188-mux-con";
						rockchip,bits = <0xe 0x2>;
						clocks = <0x3d 0x10 0x2b>;
						clock-output-names = "aclk_vio1";
						#clock-cells = <0x0>;
						#clock-init-cells = <0x1>;
						linux,phandle = <0x49>;
						phandle = <0x49>;
					};
				};

				sel-con@00e0 {
					compatible = "rockchip,rk3188-selcon";
					reg = <0xe0 0x4>;
					#address-cells = <0x1>;
					#size-cells = <0x1>;

					clk_vepu_div {
						compatible = "rockchip,rk3188-div-con";
						rockchip,bits = <0x0 0x5>;
						clocks = <0x6>;
						clock-output-names = "clk_vepu";
						rockchip,div-type = <0x0>;
						#clock-cells = <0x0>;
						rockchip,clkops-idx = <0x1>;
					};

					clk_vepu_mux {
						compatible = "rockchip,rk3188-mux-con";
						rockchip,bits = <0x6 0x2>;
						clocks = <0xf 0x10 0x2b>;
						clock-output-names = "clk_vepu";
						#clock-cells = <0x0>;
						#clock-init-cells = <0x1>;
						linux,phandle = <0x6>;
						phandle = <0x6>;
					};

					clk_vdpu_div {
						compatible = "rockchip,rk3188-div-con";
						rockchip,bits = <0x8 0x5>;
						clocks = <0x7>;
						clock-output-names = "clk_vdpu";
						rockchip,div-type = <0x0>;
						#clock-cells = <0x0>;
						rockchip,clkops-idx = <0x1>;
					};

					clk_vdpu_mux {
						compatible = "rockchip,rk3188-mux-con";
						rockchip,bits = <0xe 0x2>;
						clocks = <0xf 0x10 0x2b>;
						clock-output-names = "clk_vdpu";
						#clock-cells = <0x0>;
						#clock-init-cells = <0x1>;
						linux,phandle = <0x7>;
						phandle = <0x7>;
					};
				};

				sel-con@00e4 {
					compatible = "rockchip,rk3188-selcon";
					reg = <0xe4 0x4>;
					#address-cells = <0x1>;
					#size-cells = <0x1>;

					pclk_pd_pmu_div {
						compatible = "rockchip,rk3188-div-con";
						rockchip,bits = <0x0 0x5>;
						clocks = <0x10>;
						clock-output-names = "pclk_pd_pmu";
						rockchip,div-type = <0x0>;
						#clock-cells = <0x0>;
						#clock-init-cells = <0x1>;
						linux,phandle = <0x64>;
						phandle = <0x64>;
					};

					pclk_pd_alive {
						compatible = "rockchip,rk3188-div-con";
						rockchip,bits = <0x8 0x5>;
						clocks = <0x10>;
						clock-output-names = "pclk_pd_alive";
						rockchip,div-type = <0x0>;
						#clock-cells = <0x0>;
						#clock-init-cells = <0x1>;
						linux,phandle = <0x70>;
						phandle = <0x70>;
					};
				};

				sel-con@00e8 {
					compatible = "rockchip,rk3188-selcon";
					reg = <0xe8 0x4>;
					#address-cells = <0x1>;
					#size-cells = <0x1>;

					clk_gpu_div {
						compatible = "rockchip,rk3188-div-con";
						rockchip,bits = <0x0 0x5>;
						clocks = <0x4a>;
						clock-output-names = "clk_gpu";
						rockchip,div-type = <0x0>;
						#clock-cells = <0x0>;
						rockchip,clkops-idx = <0x1>;
						rockchip,flags = <0x100>;
					};

					clk_gpu_mux {
						compatible = "rockchip,rk3188-mux-con";
						rockchip,bits = <0x6 0x2>;
						clocks = <0xf 0x10 0x2b 0x1f>;
						clock-output-names = "clk_gpu";
						#clock-cells = <0x0>;
						#clock-init-cells = <0x1>;
						linux,phandle = <0x4a>;
						phandle = <0x4a>;
					};

					clk_sdio1_div {
						compatible = "rockchip,rk3188-div-con";
						rockchip,bits = <0x8 0x6>;
						clocks = <0x4b>;
						clock-output-names = "clk_sdio1";
						rockchip,div-type = <0x0>;
						#clock-cells = <0x0>;
						rockchip,clkops-idx = <0x3>;
					};

					clk_sdio1_mux {
						compatible = "rockchip,rk3188-mux-con";
						rockchip,bits = <0xe 0x2>;
						clocks = <0xf 0x10 0x2>;
						clock-output-names = "clk_sdio1";
						#clock-cells = <0x0>;
						linux,phandle = <0x4b>;
						phandle = <0x4b>;
					};
				};

				sel-con@00ec {
					compatible = "rockchip,rk3188-selcon";
					reg = <0xec 0x4>;
					#address-cells = <0x1>;
					#size-cells = <0x1>;

					clk_tsp_div {
						compatible = "rockchip,rk3188-div-con";
						rockchip,bits = <0x0 0x5>;
						clocks = <0x4c>;
						clock-output-names = "clk_tsp";
						rockchip,div-type = <0x0>;
						#clock-cells = <0x0>;
						rockchip,clkops-idx = <0x1>;
					};

					clk_tsp_mux {
						compatible = "rockchip,rk3188-mux-con";
						rockchip,bits = <0x6 0x2>;
						clocks = <0xf 0x10 0x1f>;
						clock-output-names = "clk_tsp";
						#clock-cells = <0x0>;
						#clock-init-cells = <0x1>;
						linux,phandle = <0x4c>;
						phandle = <0x4c>;
					};

					clk_tspout_div {
						compatible = "rockchip,rk3188-div-con";
						rockchip,bits = <0x8 0x5>;
						clocks = <0x4d>;
						clock-output-names = "clk_tspout";
						rockchip,div-type = <0x0>;
						#clock-cells = <0x0>;
						rockchip,clkops-idx = <0x1>;
					};

					clk_tspout_mux {
						compatible = "rockchip,rk3188-mux-con";
						rockchip,bits = <0xe 0x2>;
						clocks = <0xf 0x10 0x1f 0x4e>;
						clock-output-names = "clk_tspout";
						#clock-cells = <0x0>;
						#clock-init-cells = <0x1>;
						linux,phandle = <0x4d>;
						phandle = <0x4d>;
					};
				};

				sel-con@00f0 {
					compatible = "rockchip,rk3188-selcon";
					reg = <0xf0 0x4>;
					#address-cells = <0x1>;
					#size-cells = <0x1>;

					clk_core0_div {
						compatible = "rockchip,rk3188-div-con";
						rockchip,bits = <0x0 0x3>;
						clocks = <0x9>;
						clock-output-names = "clk_core0";
						rockchip,div-type = <0x0>;
						#clock-cells = <0x0>;
						rockchip,clkops-idx = <0xc>;
						linux,phandle = <0x67>;
						phandle = <0x67>;
					};

					clk_core1_div {
						compatible = "rockchip,rk3188-div-con";
						rockchip,bits = <0x4 0x3>;
						clocks = <0x9>;
						clock-output-names = "clk_core1";
						rockchip,div-type = <0x0>;
						#clock-cells = <0x0>;
						rockchip,clkops-idx = <0xc>;
						linux,phandle = <0x68>;
						phandle = <0x68>;
					};

					clk_core2_div {
						compatible = "rockchip,rk3188-div-con";
						rockchip,bits = <0x8 0x3>;
						clocks = <0x9>;
						clock-output-names = "clk_core2";
						rockchip,div-type = <0x0>;
						#clock-cells = <0x0>;
						rockchip,clkops-idx = <0xc>;
						linux,phandle = <0x69>;
						phandle = <0x69>;
					};

					clk_core3_div {
						compatible = "rockchip,rk3188-div-con";
						rockchip,bits = <0xc 0x3>;
						clocks = <0x9>;
						clock-output-names = "clk_core3";
						rockchip,div-type = <0x0>;
						#clock-cells = <0x0>;
						rockchip,clkops-idx = <0xc>;
						linux,phandle = <0x6a>;
						phandle = <0x6a>;
					};
				};

				sel-con@00f4 {
					compatible = "rockchip,rk3188-selcon";
					reg = <0xf4 0x4>;
					#address-cells = <0x1>;
					#size-cells = <0x1>;

					clk_l2ram_div {
						compatible = "rockchip,rk3188-div-con";
						rockchip,bits = <0x0 0x3>;
						clocks = <0x9>;
						clock-output-names = "clk_l2ram";
						rockchip,div-type = <0x0>;
						#clock-cells = <0x0>;
						rockchip,clkops-idx = <0xc>;
						linux,phandle = <0x6b>;
						phandle = <0x6b>;
					};

					atclk_core_div {
						compatible = "rockchip,rk3188-div-con";
						rockchip,bits = <0x4 0x5>;
						clocks = <0x9>;
						clock-output-names = "atclk_core";
						rockchip,div-type = <0x0>;
						#clock-cells = <0x0>;
						rockchip,clkops-idx = <0xc>;
						linux,phandle = <0x6e>;
						phandle = <0x6e>;
					};

					pclk_core_dbg_div {
						compatible = "rockchip,rk3188-div-con";
						rockchip,bits = <0x9 0x5>;
						clocks = <0x9>;
						clock-output-names = "pclk_dbg_src";
						rockchip,div-type = <0x0>;
						#clock-cells = <0x0>;
						rockchip,clkops-idx = <0xc>;
						linux,phandle = <0x6f>;
						phandle = <0x6f>;
					};
				};

				sel-con@00f8 {
					compatible = "rockchip,rk3188-selcon";
					reg = <0xf8 0x4>;
					#address-cells = <0x1>;
					#size-cells = <0x1>;

					clk_nandc0_div {
						compatible = "rockchip,rk3188-div-con";
						rockchip,bits = <0x0 0x5>;
						clocks = <0x4f>;
						clock-output-names = "clk_nandc0";
						rockchip,div-type = <0x0>;
						#clock-cells = <0x0>;
						rockchip,clkops-idx = <0x1>;
					};

					clk_nandc0_mux {
						compatible = "rockchip,rk3188-mux-con";
						rockchip,bits = <0x7 0x1>;
						clocks = <0xf 0x10>;
						clock-output-names = "clk_nandc0";
						#clock-cells = <0x0>;
						linux,phandle = <0x4f>;
						phandle = <0x4f>;
					};

					clk_nandc1_div {
						compatible = "rockchip,rk3188-div-con";
						rockchip,bits = <0x8 0x5>;
						clocks = <0x50>;
						clock-output-names = "clk_nandc1";
						rockchip,div-type = <0x0>;
						#clock-cells = <0x0>;
						rockchip,clkops-idx = <0x1>;
					};

					clk_nandc1_mux {
						compatible = "rockchip,rk3188-mux-con";
						rockchip,bits = <0xf 0x1>;
						clocks = <0xf 0x10>;
						clock-output-names = "clk_nandc1";
						#clock-cells = <0x0>;
						linux,phandle = <0x50>;
						phandle = <0x50>;
					};
				};

				sel-con@00fc {
					compatible = "rockchip,rk3188-selcon";
					reg = <0xfc 0x4>;
					#address-cells = <0x1>;
					#size-cells = <0x1>;

					clk_spi2_div {
						compatible = "rockchip,rk3188-div-con";
						rockchip,bits = <0x0 0x7>;
						clocks = <0x51>;
						clock-output-names = "clk_spi2";
						rockchip,div-type = <0x0>;
						#clock-cells = <0x0>;
						rockchip,clkops-idx = <0x1>;
					};

					clk_spi2_mux {
						compatible = "rockchip,rk3188-mux-con";
						rockchip,bits = <0x7 0x1>;
						clocks = <0xf 0x10>;
						clock-output-names = "clk_spi2";
						#clock-cells = <0x0>;
						linux,phandle = <0x51>;
						phandle = <0x51>;
					};

					aclk_hevc_div {
						compatible = "rockchip,rk3188-div-con";
						rockchip,bits = <0x8 0x5>;
						clocks = <0x52>;
						clock-output-names = "aclk_hevc";
						rockchip,div-type = <0x0>;
						#clock-cells = <0x0>;
						rockchip,clkops-idx = <0x1>;
						rockchip,flags = <0x100>;
					};

					aclk_hevc_mux {
						compatible = "rockchip,rk3188-mux-con";
						rockchip,bits = <0xe 0x2>;
						clocks = <0xf 0x10 0x1f>;
						clock-output-names = "aclk_hevc";
						#clock-cells = <0x0>;
						#clock-init-cells = <0x1>;
						linux,phandle = <0x52>;
						phandle = <0x52>;
					};
				};

				sel-con@0100 {
					compatible = "rockchip,rk3188-selcon";
					reg = <0x100 0x4>;
					#address-cells = <0x1>;
					#size-cells = <0x1>;

					spdif_8ch_div {
						compatible = "rockchip,rk3188-div-con";
						rockchip,bits = <0x0 0x7>;
						clocks = <0x1b>;
						clock-output-names = "spdif_8ch_div";
						rockchip,div-type = <0x0>;
						#clock-cells = <0x0>;
						linux,phandle = <0x53>;
						phandle = <0x53>;
					};

					spdif_8ch_clk_mux {
						compatible = "rockchip,rk3188-mux-con";
						rockchip,bits = <0x8 0x2>;
						clocks = <0x53 0x54 0x19>;
						clock-output-names = "clk_spdif_8ch";
						#clock-cells = <0x0>;
						rockchip,clkops-idx = <0xe>;
						rockchip,flags = <0x4>;
						linux,phandle = <0x60>;
						phandle = <0x60>;
					};

					hclk_hevc_div {
						compatible = "rockchip,rk3188-div-con";
						rockchip,bits = <0xc 0x2>;
						clocks = <0x52>;
						clock-output-names = "hclk_hevc";
						rockchip,div-type = <0x0>;
						#clock-cells = <0x0>;
						#clock-init-cells = <0x1>;
					};
				};

				sel-con@0104 {
					compatible = "rockchip,rk3188-selcon";
					reg = <0x104 0x4>;
					#address-cells = <0x1>;
					#size-cells = <0x1>;

					spdif_8ch_frac {
						compatible = "rockchip,rk3188-frac-con";
						clocks = <0x53>;
						clock-output-names = "spdif_8ch_frac";
						rockchip,bits = <0x0 0x20>;
						rockchip,clkops-idx = <0x5>;
						#clock-cells = <0x0>;
						linux,phandle = <0x54>;
						phandle = <0x54>;
					};
				};

				sel-con@0108 {
					compatible = "rockchip,rk3188-selcon";
					reg = <0x108 0x4>;
					#address-cells = <0x1>;
					#size-cells = <0x1>;

					clk_hevc_cabac_div {
						compatible = "rockchip,rk3188-div-con";
						rockchip,bits = <0x0 0x5>;
						clocks = <0x55>;
						clock-output-names = "clk_hevc_cabac";
						rockchip,div-type = <0x0>;
						#clock-cells = <0x0>;
						rockchip,clkops-idx = <0x1>;
						rockchip,flags = <0x100>;
					};

					clk_hevc_cabac_mux {
						compatible = "rockchip,rk3188-mux-con";
						rockchip,bits = <0x6 0x2>;
						clocks = <0xf 0x10 0x1f>;
						clock-output-names = "clk_hevc_cabac";
						#clock-cells = <0x0>;
						#clock-init-cells = <0x1>;
						linux,phandle = <0x55>;
						phandle = <0x55>;
					};

					clk_hevc_core_div {
						compatible = "rockchip,rk3188-div-con";
						rockchip,bits = <0x8 0x5>;
						clocks = <0x56>;
						clock-output-names = "clk_hevc_core";
						rockchip,div-type = <0x0>;
						#clock-cells = <0x0>;
						rockchip,clkops-idx = <0x1>;
						rockchip,flags = <0x100>;
					};

					clk_hevc_core_mux {
						compatible = "rockchip,rk3188-mux-con";
						rockchip,bits = <0xe 0x2>;
						clocks = <0xf 0x10 0x1f>;
						clock-output-names = "clk_hevc_core";
						#clock-cells = <0x0>;
						#clock-init-cells = <0x1>;
						linux,phandle = <0x56>;
						phandle = <0x56>;
					};
				};
			};

			clk_gate_cons {
				compatible = "rockchip,rk-gate-cons";
				#address-cells = <0x1>;
				#size-cells = <0x1>;
				ranges;

				gate-clk@0160 {
					compatible = "rockchip,rk3188-gate-clk";
					reg = <0x160 0x4>;
					clocks = <0x12 0xa 0x10 0xe 0x57 0x58 0x12 0xe 0x3a 0x10 0x10 0x3d 0x2 0x12 0x12 0x12>;
					clock-output-names = "reserved", "reserved", "clk_arm_gpll", "g_aclk_bus", "hclk_bus", "pclk_bus", "reserved", "aclk_bus_2pmu", "reserved", "reserved", "reserved", "reserved", "clk_acc_efuse", "reserved", "reserved", "reserved";
					rockchip,suspend-clkgating-setting = <0xfff 0xfff>;
					#clock-cells = <0x1>;
					linux,phandle = <0xb>;
					phandle = <0xb>;
				};

				gate-clk@0164 {
					compatible = "rockchip,rk3188-gate-clk";
					reg = <0x164 0x4>;
					clocks = <0x2 0x2 0x2 0x2 0x2 0x2 0x12 0x12 0x26 0x27 0x2c 0x2d 0x2e 0x2f 0x30 0x31>;
					clock-output-names = "clk_timer0", "clk_timer1", "clk_timer2", "clk_timer3", "clk_timer4", "clk_timer5", "reserved", "reserved", "clk_uart0_pll", "uart0_frac", "clk_uart1_div", "uart1_frac", "clk_uart2_div", "uart2_frac", "clk_uart3_div", "uart3_frac";
					rockchip,suspend-clkgating-setting = <0x0 0x0>;
					#clock-cells = <0x1>;
				};

				gate-clk@0168 {
					compatible = "rockchip,rk3188-gate-clk";
					reg = <0x168 0x4>;
					clocks = <0x21 0x21 0x59 0x5a 0x12 0x32 0x34 0x5b 0x5c 0x37 0x38 0x51 0x14 0x15 0x12 0x12>;
					clock-output-names = "aclk_peri", "reserved", "hclk_peri", "pclk_peri", "reserved", "clk_mac_pll", "clk_hsadc_pll", "clk_tsadc", "clk_saradc", "clk_spi0", "clk_spi1", "clk_spi2", "clk_uart4_div", "uart4_frac", "reserved", "reserved";
					rockchip,suspend-clkgating-setting = <0xf 0xf>;
					#clock-cells = <0x1>;
				};

				gate-clk@016c {
					compatible = "rockchip,rk3188-gate-clk";
					reg = <0x16c 0x4>;
					clocks = <0x48 0x3e 0x49 0x45 0x47 0x46 0x23 0x3c 0x12 0x6 0x12 0x7 0x5d 0x3f 0x1e 0x20>;
					clock-output-names = "aclk_vio0", "dclk_lcdc0", "aclk_vio1", "dclk_lcdc1", "clk_rga", "aclk_rga", "ehci1phy_480m", "clk_cif_pll", "reserved", "clk_vepu", "reserved", "clk_vdpu", "clk_edp_24m", "clk_edp", "clk_isp", "clk_isp_jpe";
					rockchip,suspend-clkgating-setting = <0x0 0x0>;
					#clock-cells = <0x1>;
				};

				gate-clk@0170 {
					compatible = "rockchip,rk3188-gate-clk";
					reg = <0x170 0x4>;
					clocks = <0x5e 0x16 0x17 0x1a 0x1c 0x1d 0x5f 0x53 0x54 0x60 0x4c 0x4d 0x39 0x39 0x61 0x12>;
					clock-output-names = "clk_i2s_out", "clk_i2s_pll", "i2s_frac", "clk_i2s", "spdif_div", "spdif_frac", "clk_spdif", "spdif_8ch_div", "spdif_8ch_frac", "clk_spdif_8ch", "clk_tsp", "clk_tspout", "reserved", "reserved", "clk_jtag", "reserved";
					rockchip,suspend-clkgating-setting = <0xf000 0xf000>;
					#clock-cells = <0x1>;
				};

				gate-clk@0174 {
					compatible = "rockchip,rk3188-gate-clk";
					reg = <0x174 0x4>;
					clocks = <0x62 0x62 0x62 0x62 0x63 0x4f 0x50 0x4a 0x64 0x2 0x2 0x11 0x2 0x2 0x2b 0x2>;
					clock-output-names = "g_clk_mac_rx", "g_clk_mac_tx", "g_clk_mac_ref", "g_mac_refout", "clk_crypto", "clk_nandc0", "clk_nandc1", "clk_gpu", "pclk_pd_pmu", "g_clk_pvtm_core", "g_clk_pvtm_gpu", "g_hdmi_cec_clk", "g_hdmi_hdcp_clk", "g_ps2c_clk", "usbphy_480m", "g_mipidsi_24m";
					rockchip,suspend-clkgating-setting = <0x100 0x100>;
					#clock-cells = <0x1>;
				};

				gate-clk@0178 {
					compatible = "rockchip,rk3188-gate-clk";
					reg = <0x178 0x4>;
					clocks = <0x59 0x5a 0x21 0x21 0x5a 0x5a 0x5a 0x5a 0x5a 0x5a 0x12 0x5a 0x5a 0x5a 0x5a 0x5a>;
					clock-output-names = "g_hp_matrix", "g_pp_axi_matrix", "g_ap_axi_matrix", "g_aclk_dmac2", "g_pclk_spi0", "g_pclk_spi1", "g_pclk_spi2", "g_pclk_ps2c", "g_pclk_uart0", "g_pclk_uart1", "reserved", "g_pclk_uart3", "g_pclk_uart4", "g_pclk_i2c1", "g_pclk_i2c3", "g_pclk_i2c4";
					rockchip,suspend-clkgating-setting = <0x3 0x3>;
					#clock-cells = <0x1>;
				};

				gate-clk@017c {
					compatible = "rockchip,rk3188-gate-clk";
					reg = <0x17c 0x4>;
					clocks = <0x5a 0x5a 0x5a 0x5a 0x59 0x59 0x59 0x59 0x59 0x59 0x59 0x21 0x59 0x59 0x59 0x59>;
					clock-output-names = "g_pclk_i2c5", "g_pclk_saradc", "g_pclk_tsadc", "g_pclk_sim", "g_hclk_otg0", "g_pmu_hclk_otg0", "g_hclk_host0", "g_hclk_host1", "g_hclk_ehci1", "g_hclk_usb_peri", "g_hp_ahb_arbi", "g_aclk_peri_niu", "g_h_emem_peri", "g_hclk_mem_peri", "g_hclk_nandc0", "g_hclk_nandc1";
					rockchip,suspend-clkgating-setting = <0xc00 0xc000>;
					#clock-cells = <0x1>;
				};

				gate-clk@0180 {
					compatible = "rockchip,rk3188-gate-clk";
					reg = <0x180 0x4>;
					clocks = <0x21 0x5a 0x21 0x59 0x59 0x59 0x59 0x59 0x59 0x65 0x66 0x4e 0x21 0x12 0x12 0x12>;
					clock-output-names = "g_aclk_gmac", "g_pclk_gmac", "g_hclk_gps", "g_hclk_sdmmc", "g_hclk_sdio0", "g_hclk_sdio1", "g_hclk_emmc", "g_hclk_hsadc", "g_hclk_tsp", "g_hsadc_0_tsp", "g_hsadc_1_tsp", "g_clk_27m_tsp", "g_aclk_peri_mmu", "reserved", "reserved", "reserved";
					rockchip,suspend-clkgating-setting = <0x0 0x0>;
					#clock-cells = <0x1>;
				};

				gate-clk@0184 {
					compatible = "rockchip,rk3188-gate-clk";
					reg = <0x184 0x4>;
					clocks = <0x12 0x12 0x12 0x12 0x12 0x12 0x12 0x12 0x12 0x12 0x12 0x12 0x12 0x12 0x12 0x12>;
					clock-output-names = "reserved", "reserved", "reserved", "reserved", "reserved", "reserved", "reserved", "reserved", "reserved", "reserved", "reserved", "reserved", "reserved", "reserved", "reserved", "reserved";
					rockchip,suspend-clkgating-setting = <0x0 0x0>;
					#clock-cells = <0x1>;
				};

				gate-clk@0188 {
					compatible = "rockchip,rk3188-gate-clk";
					reg = <0x188 0x4>;
					clocks = <0x58 0x58 0x58 0x58 0xe 0xe 0xe 0xe 0x57 0x57 0x57 0x57 0xe 0xe 0x58 0x58>;
					clock-output-names = "g_pclk_pwm", "g_pclk_timer", "g_pclk_i2c0", "g_pclk_i2c2", "g_aclk_intmem", "g_clk_intmem0", "g_clk_intmem1", "g_clk_intmem2", "g_hclk_i2s", "g_hclk_rom", "g_hclk_spdif", "g_h_spdif_8ch", "g_aclk_dmac1", "g_aclk_strc_sys", "reserved", "reserved";
					rockchip,suspend-clkgating-setting = <0xf2f1 0xf2f1>;
					#clock-cells = <0x1>;
				};

				gate-clk@018c {
					compatible = "rockchip,rk3188-gate-clk";
					reg = <0x18c 0x4>;
					clocks = <0x58 0x58 0x58 0x58 0x12 0x12 0xe 0x57 0xe 0x58 0x58 0x58 0x12 0x12 0x12 0x12>;
					clock-output-names = "reserved", "reserved", "g_p_efuse_1024", "g_pclk_tzpc", "reserved", "reserved", "g_aclk_crypto", "g_hclk_crypto", "g_aclk_ccp", "g_pclk_uart2", "g_p_efuse_256", "g_pclk_rkpwm", "reserved", "reserved", "reserved", "reserved";
					rockchip,suspend-clkgating-setting = <0x33 0x33>;
					#clock-cells = <0x1>;
				};

				gate-clk@0190 {
					compatible = "rockchip,rk3188-gate-clk";
					reg = <0x190 0x4>;
					clocks = <0x67 0x68 0x69 0x6a 0x6b 0x6c 0x6d 0x6e 0x6f 0x6f 0x6f 0x6f 0x12 0x12 0x12 0x12>;
					clock-output-names = "clk_core0", "clk_core1", "clk_core2", "clk_core3", "clk_l2ram", "aclk_core_m0", "aclk_core_mp", "atclk_core", "pclk_dbg_src", "g_dbg_core_clk", "g_cs_dbg_clk", "g_pclk_core_niu", "reserved", "reserved", "reserved", "reserved";
					rockchip,suspend-clkgating-setting = <0xff1 0xff1>;
					#clock-cells = <0x1>;
				};

				gate-clk@0194 {
					compatible = "rockchip,rk3188-gate-clk";
					reg = <0x194 0x4>;
					clocks = <0x22 0x24 0x4b 0x25 0x2 0x2 0x2 0x11 0xd 0x19 0x2 0x2 0x12 0x52 0x55 0x56>;
					clock-output-names = "clk_sdmmc", "clk_sdio0", "clk_sdio1", "clk_emmc", "clk_otgphy0", "clk_otgphy1", "clk_otgphy2", "clk_otg_adp", "g_clk_c2c_host", "g_clk_ehci1_12m", "g_clk_lcdc_pwm0", "g_clk_lcdc_pwm1", "g_clk_wifi", "aclk_hevc", "clk_hevc_cabac", "clk_hevc_core";
					rockchip,suspend-clkgating-setting = <0x0 0x0>;
					#clock-cells = <0x1>;
					linux,phandle = <0x3>;
					phandle = <0x3>;
				};

				gate-clk@0198 {
					compatible = "rockchip,rk3188-gate-clk";
					reg = <0x198 0x4>;
					clocks = <0x12 0x70 0x70 0x70 0x70 0x70 0x70 0x70 0x70 0x12 0x12 0x70 0x70 0x12 0x12 0x12>;
					clock-output-names = "reserved", "g_pclk_gpio1", "g_pclk_gpio2", "g_pclk_gpio3", "g_pclk_gpio4", "g_pclk_gpio5", "g_pclk_gpio6", "g_pclk_gpio7", "g_pclk_gpio8", "reserved", "reserved", "g_pclk_grf", "g_p_alive_niu", "reserved", "reserved", "reserved";
					rockchip,suspend-clkgating-setting = <0x19fe 0x19fe>;
					#clock-cells = <0x1>;
				};

				gate-clk@019c {
					compatible = "rockchip,rk3188-gate-clk";
					reg = <0x19c 0x4>;
					clocks = <0x46 0x71 0x40 0xb 0x71 0x12 0x40 0xb 0x71 0x40 0xc 0x71 0x12 0x12 0x48 0x49 0x46 0x40 0xb 0x71>;
					clock-output-names = "reserved", "g_hclk_rga", "g_aclk_iep", "g_hclk_iep", "g_aclk_lcdc_iep", "g_aclk_lcdc0", "g_hclk_lcdc0", "g_aclk_lcdc1", "g_hclk_lcdc1", "reserved", "reserved", "g_aclk_vio0_niu", "g_aclk_vio1_niu", "reserved", "g_aclk_vip", "g_hclk_vip";
					rockchip,suspend-clkgating-setting = <0x0 0x0>;
					#clock-cells = <0x1>;
					linux,phandle = <0x40>;
					phandle = <0x40>;
				};

				gate-clk@01a0 {
					compatible = "rockchip,rk3188-gate-clk";
					reg = <0x1a0 0x4>;
					clocks = <0x72 0x71 0x40 0xc 0x73 0x71 0x71 0x71 0x71 0x71 0x71 0x12 0x12 0x12 0x12 0x12 0x12>;
					clock-output-names = "g_pclkin_cif", "g_hclk_isp", "g_aclk_isp", "g_pclkin_isp", "g_p_mipi_dsi0", "g_p_mipi_dsi1", "g_p_mipi_csi", "g_pclk_lvds_phy", "g_pclk_edp_ctrl", "g_p_hdmi_ctrl", "reserved", "reserved", "reserved", "reserved", "reserved", "reserved";
					rockchip,suspend-clkgating-setting = <0x0 0x0>;
					#clock-cells = <0x1>;
					linux,phandle = <0x5>;
					phandle = <0x5>;
				};

				gate-clk@01a4 {
					compatible = "rockchip,rk3188-gate-clk";
					reg = <0x1a4 0x4>;
					clocks = <0x64 0x64 0x64 0x64 0x64 0x12 0x12 0x12 0x12 0x12 0x12 0x12 0x12 0x12 0x12 0x12>;
					clock-output-names = "g_pclk_pmu", "g_pclk_intmem1", "g_pclk_pmu_niu", "g_pclk_sgrf", "g_pclk_gpio0", "reserved", "reserved", "reserved", "reserved", "reserved", "reserved", "reserved", "reserved", "reserved", "reserved", "reserved";
					rockchip,suspend-clkgating-setting = <0x1f 0x1f>;
					#clock-cells = <0x1>;
				};

				gate-clk@01a8 {
					compatible = "rockchip,rk3188-gate-clk";
					reg = <0x1a8 0x4>;
					clocks = <0x4a 0x12 0x12 0x12 0x12 0x12 0x12 0x12 0x12 0x12 0x12 0x12 0x12 0x12 0x12 0x12>;
					clock-output-names = "reserved", "reserved", "reserved", "reserved", "reserved", "reserved", "reserved", "reserved", "reserved", "reserved", "reserved", "reserved", "reserved", "reserved", "reserved", "reserved";
					rockchip,suspend-clkgating-setting = <0x0 0x0>;
					#clock-cells = <0x1>;
				};
			};
		};
	};

	arm-pmu {
		compatible = "arm,cortex-a12-pmu";
		interrupts = <0x0 0x97 0x4 0x0 0x98 0x4 0x0 0x99 0x4 0x0 0x9a 0x4>;
		interrupt-affinity = <0x74 0x75 0x76 0x77>;
	};

	cpus {
		#address-cells = <0x1>;
		#size-cells = <0x0>;
		enable-method = "rockchip,rk3066-smp";
		rockchip,pmu = <0x78>;

		cpu@500 {
			device_type = "cpu";
			compatible = "arm,cortex-a12";
			reg = <0x500>;
			resets = <0x79 0x0>;
			operating-points-v2 = <0x7a>;
			#cooling-cells = <0x2>;
			dynamic-power-coefficient = <0x142>;
			clocks = <0x79 0x6>;
			cpu0-supply = <0x7b>;
			linux,phandle = <0x74>;
			phandle = <0x74>;
		};

		cpu@501 {
			device_type = "cpu";
			compatible = "arm,cortex-a12";
			reg = <0x501>;
			resets = <0x79 0x1>;
			operating-points-v2 = <0x7a>;
			linux,phandle = <0x75>;
			phandle = <0x75>;
		};

		cpu@502 {
			device_type = "cpu";
			compatible = "arm,cortex-a12";
			reg = <0x502>;
			resets = <0x79 0x2>;
			operating-points-v2 = <0x7a>;
			linux,phandle = <0x76>;
			phandle = <0x76>;
		};

		cpu@503 {
			device_type = "cpu";
			compatible = "arm,cortex-a12";
			reg = <0x503>;
			resets = <0x79 0x3>;
			operating-points-v2 = <0x7a>;
			linux,phandle = <0x77>;
			phandle = <0x77>;
		};
	};

	opp_table0 {
		compatible = "operating-points-v2";
		opp-shared;
		nvmem-cells = <0x7c>;
		nvmem-cell-names = "cpu_leakage";
		linux,phandle = <0x7a>;
		phandle = <0x7a>;

		opp-126000000 {
			opp-hz = <0x0 0x7829b80>;
			opp-microvolt = <0xdbba0>;
			clock-latency-ns = <0x9c40>;
		};

		opp-216000000 {
			opp-hz = <0x0 0xcdfe600>;
			opp-microvolt = <0xdbba0>;
			clock-latency-ns = <0x9c40>;
		};

		opp-408000000 {
			opp-hz = <0x0 0x18519600>;
			opp-microvolt = <0xdbba0>;
			clock-latency-ns = <0x9c40>;
		};

		opp-600000000 {
			opp-hz = <0x0 0x23c34600>;
			opp-microvolt = <0xdbba0>;
			clock-latency-ns = <0x9c40>;
		};

		opp-696000000 {
			opp-hz = <0x0 0x297c1e00>;
			opp-microvolt = <0xe7ef0>;
			clock-latency-ns = <0x9c40>;
		};

		opp-816000000 {
			opp-hz = <0x0 0x30a32c00>;
			opp-microvolt = <0xf4240>;
			clock-latency-ns = <0x9c40>;
			opp-suspend;
		};

		opp-1008000000 {
			opp-hz = <0x0 0x3c14dc00>;
			opp-microvolt = <0x100590>;
			clock-latency-ns = <0x9c40>;
		};

		opp-1200000000 {
			opp-hz = <0x0 0x47868c00>;
			opp-microvolt = <0x10c8e0>;
			clock-latency-ns = <0x9c40>;
		};

		opp-1416000000 {
			opp-hz = <0x0 0x54667200>;
			opp-microvolt = <0x124f80>;
			clock-latency-ns = <0x9c40>;
		};

		opp-1512000000 {
			opp-hz = <0x0 0x5a1f4a00>;
			opp-microvolt = <0x13d620>;
			clock-latency-ns = <0x9c40>;
		};

		opp-1608000000 {
			opp-hz = <0x0 0x5fd82200>;
			opp-microvolt = <0x149970>;
			clock-latency-ns = <0x9c40>;
		};
	};

	amba {
		compatible = "arm,amba-bus";
		#address-cells = <0x2>;
		#size-cells = <0x2>;
		ranges;

		dma-controller@ff250000 {
			compatible = "arm,pl330", "arm,primecell";
			reg = <0x0 0xff250000 0x0 0x4000>;
			interrupts = <0x0 0x2 0x4 0x0 0x3 0x4>;
			#dma-cells = <0x1>;
			arm,pl330-broken-no-flushp;
			peripherals-req-type-burst;
			clocks = <0x79 0xc2>;
			clock-names = "apb_pclk";
			linux,phandle = <0x92>;
			phandle = <0x92>;
		};

		dma-controller@ff600000 {
			compatible = "arm,pl330", "arm,primecell";
			reg = <0x0 0xff600000 0x0 0x4000>;
			interrupts = <0x0 0x0 0x4 0x0 0x1 0x4>;
			#dma-cells = <0x1>;
			arm,pl330-broken-no-flushp;
			peripherals-req-type-burst;
			clocks = <0x79 0xc1>;
			clock-names = "apb_pclk";
			status = "disabled";
		};

		dma-controller@ffb20000 {
			compatible = "arm,pl330", "arm,primecell";
			reg = <0x0 0xffb20000 0x0 0x4000>;
			interrupts = <0x0 0x0 0x4 0x0 0x1 0x4>;
			#dma-cells = <0x1>;
			arm,pl330-broken-no-flushp;
			peripherals-req-type-burst;
			clocks = <0x79 0xc1>;
			clock-names = "apb_pclk";
			linux,phandle = <0xda>;
			phandle = <0xda>;
		};
	};

	reserved-memory {
		#address-cells = <0x2>;
		#size-cells = <0x2>;
		ranges;

		dma-unusable@fe000000 {
			reg = <0x0 0xfe000000 0x0 0x1000000>;
		};
	};

	oscillator {
		compatible = "fixed-clock";
		clock-frequency = <0x16e3600>;
		clock-output-names = "xin24m";
		#clock-cells = <0x0>;
		linux,phandle = <0x2>;
		phandle = <0x2>;
	};

	timer {
		compatible = "arm,armv7-timer";
		arm,cpu-registers-not-fw-configured;
		interrupts = <0x1 0xd 0xf04 0x1 0xe 0xf04 0x1 0xb 0xf04 0x1 0xa 0xf04>;
		clock-frequency = <0x16e3600>;
	};

	display-subsystem {
		compatible = "rockchip,display-subsystem";
		ports = <0x7d 0x7e>;
	};

	dwmmc@ff0c0000 {
		compatible = "rockchip,rk3288-dw-mshc";
		clock-freq-min-max = <0x61a80 0x8f0d180>;
		clocks = <0x79 0x1c8 0x79 0x44 0x79 0x72 0x79 0x76>;
		clock-names = "biu", "ciu", "ciu-drive", "ciu-sample";
		fifo-depth = <0x100>;
		interrupts = <0x0 0x20 0x4>;
		reg = <0x0 0xff0c0000 0x0 0x4000>;
		status = "okay";
		bus-width = <0x4>;
		cap-mmc-highspeed;
		cap-sd-highspeed;
		card-detect-delay = <0xc8>;
		disable-wp;
		num-slots = <0x1>;
		pinctrl-names = "default";
		pinctrl-0 = <0x7f 0x80 0x81 0x82>;
		supports-sd;
		vmmc-supply = <0x83>;
		vqmmc-supply = <0x84>;
	};

	dwmmc@ff0d0000 {
		compatible = "rockchip,rk3288-dw-mshc";
		clock-freq-min-max = <0x30d40 0x2faf080>;
		clocks = <0x79 0x1c9 0x79 0x45 0x79 0x73 0x79 0x77>;
		clock-names = "biu", "ciu", "ciu-drive", "ciu-sample";
		fifo-depth = <0x100>;
		interrupts = <0x0 0x21 0x4>;
		reg = <0x0 0xff0d0000 0x0 0x4000>;
		status = "okay";
		clock-frequency = <0x2faf080>;
		bus-width = <0x4>;
		cap-sd-highspeed;
		cap-sdio-irq;
		disable-wp;
		keep-power-in-suspend;
		mmc-pwrseq = <0x85>;
		non-removable;
		num-slots = <0x1>;
		pinctrl-names = "default";
		pinctrl-0 = <0x86 0x87 0x88 0x89>;
		sd-uhs-sdr104;
		supports-sdio;
		vmmc-supply = <0x8a>;
		vqmmc-supply = <0x8b>;
	};

	dwmmc@ff0e0000 {
		compatible = "rockchip,rk3288-dw-mshc";
		clock-freq-min-max = <0x61a80 0x8f0d180>;
		clocks = <0x79 0x1ca 0x79 0x46 0x79 0x74 0x79 0x78>;
		clock-names = "biu", "ciu", "ciu-drive", "ciu-sample";
		fifo-depth = <0x100>;
		interrupts = <0x0 0x22 0x4>;
		reg = <0x0 0xff0e0000 0x0 0x4000>;
		status = "disabled";
	};

	dwmmc@ff0f0000 {
		compatible = "rockchip,rk3288-dw-mshc";
		clock-freq-min-max = <0x61a80 0x8f0d180>;
		clocks = <0x79 0x1cb 0x79 0x47 0x79 0x75 0x79 0x79>;
		clock-names = "biu", "ciu", "ciu-drive", "ciu-sample";
		fifo-depth = <0x100>;
		interrupts = <0x0 0x23 0x4>;
		reg = <0x0 0xff0f0000 0x0 0x4000>;
		status = "okay";
		supports-emmc;
		bus-width = <0x8>;
		cap-mmc-highspeed;
		disable-wp;
		non-removable;
		num-slots = <0x1>;
		pinctrl-names = "default";
		pinctrl-0 = <0x8c 0x8d 0x8e 0x8f>;
		vmmc-supply = <0x90>;
		vqmmc-supply = <0x91>;
	};

	saradc@ff100000 {
		compatible = "rockchip,saradc";
		reg = <0x0 0xff100000 0x0 0x100>;
		interrupts = <0x0 0x24 0x4>;
		#io-channel-cells = <0x1>;
		clocks = <0x79 0x49 0x79 0x15b>;
		clock-names = "saradc", "apb_pclk";
		resets = <0x79 0x57>;
		reset-names = "saradc-apb";
		status = "okay";
		vref-supply = <0x8b>;
	};

	spi@ff110000 {
		compatible = "rockchip,rk3288-spi", "rockchip,rk3066-spi";
		clocks = <0x79 0x41 0x79 0x152>;
		clock-names = "spiclk", "apb_pclk";
		dmas = <0x92 0xb 0x92 0xc>;
		dma-names = "tx", "rx";
		interrupts = <0x0 0x2c 0x4>;
		pinctrl-names = "default";
		pinctrl-0 = <0x93 0x94 0x95 0x96 0x97>;
		reg = <0x0 0xff110000 0x0 0x1000>;
		#address-cells = <0x1>;
		#size-cells = <0x0>;
		status = "okay";
	};

	spi@ff120000 {
		compatible = "rockchip,rk3288-spi", "rockchip,rk3066-spi";
		clocks = <0x79 0x42 0x79 0x153>;
		clock-names = "spiclk", "apb_pclk";
		dmas = <0x92 0xd 0x92 0xe>;
		dma-names = "tx", "rx";
		interrupts = <0x0 0x2d 0x4>;
		pinctrl-names = "default";
		pinctrl-0 = <0x98 0x99 0x9a 0x9b>;
		reg = <0x0 0xff120000 0x0 0x1000>;
		#address-cells = <0x1>;
		#size-cells = <0x0>;
		status = "disabled";
	};

	spi@ff130000 {
		compatible = "rockchip,rk3288-spi", "rockchip,rk3066-spi";
		clocks = <0x79 0x43 0x79 0x154>;
		clock-names = "spiclk", "apb_pclk";
		dmas = <0x92 0xf 0x92 0x10>;
		dma-names = "tx", "rx";
		interrupts = <0x0 0x2e 0x4>;
		pinctrl-names = "default";
		pinctrl-0 = <0x9c 0x9d 0x9e 0x9f>;
		reg = <0x0 0xff130000 0x0 0x1000>;
		#address-cells = <0x1>;
		#size-cells = <0x0>;
		status = "disabled";
	};

	i2c@ff650000 {
		compatible = "rockchip,rk3288-i2c";
		reg = <0x0 0xff650000 0x0 0x1000>;
		interrupts = <0x0 0x3c 0x4>;
		#address-cells = <0x1>;
		#size-cells = <0x0>;
		clock-names = "i2c";
		clocks = <0x79 0x14c>;
		pinctrl-names = "default";
		pinctrl-0 = <0xa0>;
		status = "okay";
		clock-frequency = <0x61a80>;

		syr827@40 {
			compatible = "silergy,syr827";
			fcs,suspend-voltage-selector = <0x1>;
			reg = <0x40>;
			regulator-name = "vdd_cpu";
			regulator-min-microvolt = <0xcf850>;
			regulator-max-microvolt = <0x149970>;
			regulator-always-on;
			regulator-boot-on;
			regulator-enable-ramp-delay = <0x12c>;
			regulator-ramp-delay = <0x1f40>;
			vin-supply = <0x8a>;
			linux,phandle = <0x7b>;
			phandle = <0x7b>;
		};

		syr828@41 {
			compatible = "silergy,syr828";
			fcs,suspend-voltage-selector = <0x1>;
			reg = <0x41>;
			regulator-name = "vdd_gpu";
			regulator-min-microvolt = <0xcf850>;
			regulator-max-microvolt = <0x149970>;
			regulator-always-on;
			regulator-ramp-delay = <0x1770>;
			vin-supply = <0x8a>;
			linux,phandle = <0x10a>;
			phandle = <0x10a>;
		};

		hym8563@51 {
			compatible = "haoyu,hym8563";
			reg = <0x51>;
			#clock-cells = <0x0>;
			clock-frequency = <0x8000>;
			clock-output-names = "xin32k";
			interrupt-parent = <0xa1>;
			interrupts = <0x4 0x2>;
			pinctrl-names = "default";
			pinctrl-0 = <0xa2>;
			linux,phandle = <0x11c>;
			phandle = <0x11c>;
		};

		act8846@5a {
			compatible = "active-semi,act8846";
			reg = <0x5a>;
			pinctrl-names = "default";
			pinctrl-0 = <0xa3 0xa4>;
			system-power-controller;
			vp1-supply = <0x8a>;
			vp2-supply = <0x8a>;
			vp3-supply = <0x8a>;
			vp4-supply = <0x8a>;
			inl1-supply = <0x8a>;
			inl2-supply = <0x8a>;
			inl3-supply = <0xa5>;

			regulators {

				REG1 {
					regulator-name = "vcc_ddr";
					regulator-min-microvolt = <0x124f80>;
					regulator-max-microvolt = <0x124f80>;
					regulator-always-on;
				};

				REG2 {
					regulator-name = "vcc_io";
					regulator-min-microvolt = <0x325aa0>;
					regulator-max-microvolt = <0x325aa0>;
					regulator-always-on;
					linux,phandle = <0x90>;
					phandle = <0x90>;
				};

				REG3 {
					regulator-name = "vdd_log";
					regulator-min-microvolt = <0x10c8e0>;
					regulator-max-microvolt = <0x10c8e0>;
					regulator-always-on;
				};

				REG4 {
					regulator-name = "vcc_20";
					regulator-min-microvolt = <0x1e8480>;
					regulator-max-microvolt = <0x1e8480>;
					regulator-always-on;
					linux,phandle = <0xa5>;
					phandle = <0xa5>;
				};

				REG5 {
					regulator-name = "vccio_sd";
					regulator-min-microvolt = <0x325aa0>;
					regulator-max-microvolt = <0x325aa0>;
					regulator-always-on;
					linux,phandle = <0x84>;
					phandle = <0x84>;
				};

				REG6 {
					regulator-name = "vdd10_lcd";
					regulator-min-microvolt = <0xf4240>;
					regulator-max-microvolt = <0xf4240>;
					regulator-always-on;
				};

				REG7 {
					regulator-name = "vcca_18";
					regulator-min-microvolt = <0x1b7740>;
					regulator-max-microvolt = <0x1b7740>;
					regulator-always-on;
				};

				REG8 {
					regulator-name = "vcca_33";
					regulator-min-microvolt = <0x325aa0>;
					regulator-max-microvolt = <0x325aa0>;
					regulator-always-on;
					linux,phandle = <0xd8>;
					phandle = <0xd8>;
				};

				REG9 {
					regulator-name = "vcc_lan";
					regulator-min-microvolt = <0x325aa0>;
					regulator-max-microvolt = <0x325aa0>;
					linux,phandle = <0xbc>;
					phandle = <0xbc>;
				};

				REG10 {
					regulator-name = "vdd_10";
					regulator-min-microvolt = <0xf4240>;
					regulator-max-microvolt = <0xf4240>;
					regulator-always-on;
					linux,phandle = <0xfc>;
					phandle = <0xfc>;
				};

				REG11 {
					regulator-name = "vcc_18";
					regulator-min-microvolt = <0x1b7740>;
					regulator-max-microvolt = <0x1b7740>;
					regulator-always-on;
					linux,phandle = <0x8b>;
					phandle = <0x8b>;
				};

				REG12 {
					regulator-name = "vcc18_lcd";
					regulator-min-microvolt = <0x1b7740>;
					regulator-max-microvolt = <0x1b7740>;
					regulator-always-on;
				};
			};
		};
	};

	i2c@ff140000 {
		compatible = "rockchip,rk3288-i2c";
		reg = <0x0 0xff140000 0x0 0x1000>;
		interrupts = <0x0 0x3e 0x4>;
		#address-cells = <0x1>;
		#size-cells = <0x0>;
		clock-names = "i2c";
		clocks = <0x79 0x14d>;
		pinctrl-names = "default";
		pinctrl-0 = <0xa6>;
		status = "okay";

		mpu6050@68 {
			compatible = "invensense,mpu6050";
			reg = <0x68>;
			interrupt-parent = <0xa7>;
			interrupts = <0xc 0x8>;
			mount-matrix = "0", "1", "0", "-1", "0", "0", "0", "0", "-1";
		};
	};

	i2c@ff150000 {
		compatible = "rockchip,rk3288-i2c";
		reg = <0x0 0xff150000 0x0 0x1000>;
		interrupts = <0x0 0x3f 0x4>;
		#address-cells = <0x1>;
		#size-cells = <0x0>;
		clock-names = "i2c";
		clocks = <0x79 0x14f>;
		pinctrl-names = "default";
		pinctrl-0 = <0xa8>;
		status = "disabled";
	};

	i2c@ff160000 {
		compatible = "rockchip,rk3288-i2c";
		reg = <0x0 0xff160000 0x0 0x1000>;
		interrupts = <0x0 0x40 0x4>;
		#address-cells = <0x1>;
		#size-cells = <0x0>;
		clock-names = "i2c";
		clocks = <0x79 0x150>;
		pinctrl-names = "default";
		pinctrl-0 = <0xa9>;
		status = "okay";
	};

	i2c@ff170000 {
		compatible = "rockchip,rk3288-i2c";
		reg = <0x0 0xff170000 0x0 0x1000>;
		interrupts = <0x0 0x41 0x4>;
		#address-cells = <0x1>;
		#size-cells = <0x0>;
		clock-names = "i2c";
		clocks = <0x79 0x151>;
		pinctrl-names = "default";
		pinctrl-0 = <0xaa>;
		status = "disabled";
	};

	serial@ff180000 {
		compatible = "rockchip,rk3288-uart", "snps,dw-apb-uart";
		reg = <0x0 0xff180000 0x0 0x100>;
		interrupts = <0x0 0x37 0x4>;
		reg-shift = <0x2>;
		reg-io-width = <0x4>;
		clocks = <0x79 0x4d 0x79 0x155>;
		clock-names = "baudclk", "apb_pclk";
		pinctrl-names = "default";
		pinctrl-0 = <0xab 0xac>;
		status = "okay";
	};

	serial@ff190000 {
		compatible = "rockchip,rk3288-uart", "snps,dw-apb-uart";
		reg = <0x0 0xff190000 0x0 0x100>;
		interrupts = <0x0 0x38 0x4>;
		reg-shift = <0x2>;
		reg-io-width = <0x4>;
		clocks = <0x79 0x4e 0x79 0x156>;
		clock-names = "baudclk", "apb_pclk";
		pinctrl-names = "default";
		pinctrl-0 = <0xad>;
		status = "okay";
	};

	serial@ff690000 {
		compatible = "rockchip,rk3288-uart", "snps,dw-apb-uart";
		reg = <0x0 0xff690000 0x0 0x100>;
		interrupts = <0x0 0x39 0x4>;
		reg-shift = <0x2>;
		reg-io-width = <0x4>;
		clocks = <0x79 0x4f 0x79 0x157>;
		clock-names = "baudclk", "apb_pclk";
		pinctrl-names = "default";
		pinctrl-0 = <0xae>;
		status = "okay";
	};

	serial@ff1b0000 {
		compatible = "rockchip,rk3288-uart", "snps,dw-apb-uart";
		reg = <0x0 0xff1b0000 0x0 0x100>;
		interrupts = <0x0 0x3a 0x4>;
		reg-shift = <0x2>;
		reg-io-width = <0x4>;
		clocks = <0x79 0x50 0x79 0x158>;
		clock-names = "baudclk", "apb_pclk";
		pinctrl-names = "default";
		pinctrl-0 = <0xaf>;
		status = "okay";
	};

	serial@ff1c0000 {
		compatible = "rockchip,rk3288-uart", "snps,dw-apb-uart";
		reg = <0x0 0xff1c0000 0x0 0x100>;
		interrupts = <0x0 0x3b 0x4>;
		reg-shift = <0x2>;
		reg-io-width = <0x4>;
		clocks = <0x79 0x51 0x79 0x159>;
		clock-names = "baudclk", "apb_pclk";
		pinctrl-names = "default";
		pinctrl-0 = <0xb0>;
		status = "disabled";
	};

	thermal-zones {

		soc-thermal {
			polling-delay-passive = <0xc8>;
			polling-delay = <0x3e8>;
			sustainable-power = <0x4b0>;
			thermal-sensors = <0xb1 0x1>;

			trips {

				trip-point@0 {
					temperature = <0x124f8>;
					hysteresis = <0x7d0>;
					type = "passive";
				};

				trip-point@1 {
					temperature = <0x14c08>;
					hysteresis = <0x7d0>;
					type = "passive";
					linux,phandle = <0xb2>;
					phandle = <0xb2>;
				};

				soc-crit {
					temperature = <0x15f90>;
					hysteresis = <0x7d0>;
					type = "critical";
				};
			};

			cooling-maps {

				map0 {
					trip = <0xb2>;
					cooling-device = <0x74 0xffffffff 0xffffffff>;
					contribution = <0x400>;
				};

				map1 {
					trip = <0xb2>;
					cooling-device = <0xb3 0xffffffff 0xffffffff>;
					contribution = <0x400>;
				};
			};
		};

		gpu-thermal {
			polling-delay-passive = <0xc8>;
			polling-delay = <0x3e8>;
			thermal-sensors = <0xb1 0x2>;
		};
	};

	tsadc@ff280000 {
		compatible = "rockchip,rk3288-tsadc";
		reg = <0x0 0xff280000 0x0 0x100>;
		interrupts = <0x0 0x25 0x4>;
		clocks = <0x79 0x48 0x79 0x15a>;
		clock-names = "tsadc", "apb_pclk";
		assigned-clocks = <0x79 0x48>;
		assigned-clock-rates = <0x1388>;
		resets = <0x79 0x9f>;
		reset-names = "tsadc-apb";
		pinctrl-names = "init", "default", "sleep";
		pinctrl-0 = <0xb4>;
		pinctrl-1 = <0xb5>;
		pinctrl-2 = <0xb4>;
		#thermal-sensor-cells = <0x1>;
		rockchip,hw-tshut-temp = <0x17318>;
		status = "okay";
		rockchip,hw-tshut-mode = <0x0>;
		rockchip,hw-tshut-polarity = <0x0>;
		linux,phandle = <0xb1>;
		phandle = <0xb1>;
	};

	ethernet@ff290000 {
		compatible = "rockchip,rk3288-gmac";
		reg = <0x0 0xff290000 0x0 0x10000>;
		interrupts = <0x0 0x1b 0x4 0x0 0x1c 0x4>;
		interrupt-names = "macirq", "eth_wake_irq";
		rockchip,grf = <0xb6>;
		clocks = <0x79 0x97 0x79 0x66 0x79 0x67 0x79 0x63 0x79 0x98 0x79 0xc4 0x79 0x15d>;
		clock-names = "stmmaceth", "mac_clk_rx", "mac_clk_tx", "clk_mac_ref", "clk_mac_refout", "aclk_mac", "pclk_mac";
		resets = <0x79 0x42>;
		reset-names = "stmmaceth";
		status = "ok";
		assigned-clocks = <0x79 0x97>;
		assigned-clock-parents = <0xb7>;
		clock_in_out = "input";
		pinctrl-names = "default";
		pinctrl-0 = <0xb8 0xb9 0xba 0xbb>;
		phy-supply = <0xbc>;
		phy-mode = "rgmii";
		snps,reset-active-low;
		snps,reset-delays-us = <0x0 0x2710 0xf4240>;
		snps,reset-gpio = <0xbd 0x8 0x1>;
		tx_delay = <0x30>;
		rx_delay = <0x10>;
	};

	usb@ff500000 {
		compatible = "generic-ehci";
		reg = <0x0 0xff500000 0x0 0x20000>;
		interrupts = <0x0 0x18 0x4>;
		clocks = <0x79 0x1c2>;
		clock-names = "usbhost";
		phys = <0xbe>;
		phy-names = "usb";
		status = "disabled";
	};

	usb@ff520000 {
		compatible = "generic-ohci";
		reg = <0x0 0xff520000 0x0 0x20000>;
		interrupts = <0x0 0x29 0x4>;
		clocks = <0x79 0x1c2>;
		clock-names = "usbhost";
		phys = <0xbe>;
		phy-names = "usb";
		status = "disabled";
	};

	usb@ff540000 {
		compatible = "rockchip,rk3288-usb", "rockchip,rk3066-usb", "snps,dwc2";
		reg = <0x0 0xff540000 0x0 0x40000>;
		interrupts = <0x0 0x19 0x4>;
		clocks = <0x79 0x1c3>;
		clock-names = "otg";
		dr_mode = "host";
		phys = <0xbf>;
		phy-names = "usb2-phy";
		status = "okay";
		pinctrl-names = "default";
		pinctrl-0 = <0xc0>;
	};

	usb@ff580000 {
		compatible = "rockchip,rk3288-usb", "rockchip,rk3066-usb", "snps,dwc2";
		reg = <0x0 0xff580000 0x0 0x40000>;
		interrupts = <0x0 0x17 0x4>;
		clocks = <0x79 0x1c1>;
		clock-names = "otg";
		dr_mode = "otg";
		g-np-tx-fifo-size = <0x10>;
		g-rx-fifo-size = <0x113>;
		g-tx-fifo-size = <0x100 0x80 0x80 0x40 0x40 0x20>;
		g-use-dma;
		phys = <0xc1>;
		phy-names = "usb2-phy";
		status = "okay";
	};

	usb@ff5c0000 {
		compatible = "generic-ehci";
		reg = <0x0 0xff5c0000 0x0 0x100>;
		interrupts = <0x0 0x1a 0x4>;
		clocks = <0x79 0x1c4>;
		clock-names = "usbhost";
		status = "disabled";
	};

	dmc@ff610000 {
		compatible = "rockchip,rk3288-dmc", "syscon";
		rockchip,cru = <0x79>;
		rockchip,grf = <0xb6>;
		rockchip,pmu = <0x78>;
		rockchip,sgrf = <0xc2>;
		rockchip,noc = <0xc3>;
		reg = <0x0 0xff610000 0x0 0x3fc 0x0 0xff620000 0x0 0x294 0x0 0xff630000 0x0 0x3fc 0x0 0xff640000 0x0 0x294>;
		rockchip,sram = <0xc4>;
		clocks = <0x79 0x16c 0x79 0x16d 0x79 0x16e 0x79 0x16f 0x79 0x6 0x79 0xc1>;
		clock-names = "pclk_ddrupctl0", "pclk_publ0", "pclk_ddrupctl1", "pclk_publ1", "arm_clk", "aclk_dmac1";
	};

	i2c@ff660000 {
		compatible = "rockchip,rk3288-i2c";
		reg = <0x0 0xff660000 0x0 0x1000>;
		interrupts = <0x0 0x3d 0x4>;
		#address-cells = <0x1>;
		#size-cells = <0x0>;
		clock-names = "i2c";
		clocks = <0x79 0x14e>;
		pinctrl-names = "default";
		pinctrl-0 = <0xc5>;
		status = "okay";
	};

	pwm@ff680000 {
		compatible = "rockchip,rk3288-pwm";
		reg = <0x0 0xff680000 0x0 0x10>;
		#pwm-cells = <0x3>;
		pinctrl-names = "default";
		pinctrl-0 = <0xc6>;
		clocks = <0x79 0x15e>;
		clock-names = "pwm";
		status = "disabled";
	};

	pwm@ff680010 {
		compatible = "rockchip,rk3288-pwm";
		reg = <0x0 0xff680010 0x0 0x10>;
		#pwm-cells = <0x3>;
		pinctrl-names = "default";
		pinctrl-0 = <0xc7>;
		clocks = <0x79 0x15e>;
		clock-names = "pwm";
		status = "okay";
		linux,phandle = <0x113>;
		phandle = <0x113>;
	};

	pwm@ff680020 {
		compatible = "rockchip,rk3288-pwm";
		reg = <0x0 0xff680020 0x0 0x10>;
		#pwm-cells = <0x3>;
		pinctrl-names = "default";
		pinctrl-0 = <0xc8>;
		clocks = <0x79 0x15e>;
		clock-names = "pwm";
		status = "disabled";
	};

	pwm@ff680030 {
		compatible = "rockchip,rk3288-pwm";
		reg = <0x0 0xff680030 0x0 0x10>;
		#pwm-cells = <0x2>;
		pinctrl-names = "default";
		pinctrl-0 = <0xc9>;
		clocks = <0x79 0x15e>;
		clock-names = "pwm";
		status = "disabled";
	};

	timer@ff6b0000 {
		compatible = "rockchip,rk3288-timer";
		reg = <0x0 0xff6b0000 0x0 0x20>;
		interrupts = <0x0 0x42 0x4>;
		clocks = <0x2 0x79 0x161>;
		clock-names = "timer", "pclk";
	};

	bus_intmem@ff700000 {
		compatible = "mmio-sram";
		reg = <0x0 0xff700000 0x0 0x18000>;
		#address-cells = <0x1>;
		#size-cells = <0x1>;
		ranges = <0x0 0x0 0xff700000 0x18000>;

		smp-sram@0 {
			compatible = "rockchip,rk3066-smp-sram";
			reg = <0x0 0x10>;
		};

		ddr-sram@1000 {
			compatible = "rockchip,rk3288-ddr-sram";
			reg = <0x1000 0x4000>;
			linux,phandle = <0xc4>;
			phandle = <0xc4>;
		};
	};

	sram@ff720000 {
		compatible = "rockchip,rk3288-pmu-sram", "mmio-sram";
		reg = <0x0 0xff720000 0x0 0x1000>;
	};

	qos@ffaa0000 {
		compatible = "syscon";
		reg = <0x0 0xffaa0000 0x0 0x20>;
		linux,phandle = <0xd6>;
		phandle = <0xd6>;
	};

	qos@ffaa0080 {
		compatible = "syscon";
		reg = <0x0 0xffaa0080 0x0 0x20>;
		linux,phandle = <0xd7>;
		phandle = <0xd7>;
	};

	qos@ffad0000 {
		compatible = "syscon";
		reg = <0x0 0xffad0000 0x0 0x20>;
		linux,phandle = <0xcb>;
		phandle = <0xcb>;
	};

	qos@ffad0100 {
		compatible = "syscon";
		reg = <0x0 0xffad0100 0x0 0x20>;
		linux,phandle = <0xcc>;
		phandle = <0xcc>;
	};

	qos@ffad0180 {
		compatible = "syscon";
		reg = <0x0 0xffad0180 0x0 0x20>;
		linux,phandle = <0xcd>;
		phandle = <0xcd>;
	};

	qos@ffad0400 {
		compatible = "syscon";
		reg = <0x0 0xffad0400 0x0 0x20>;
		linux,phandle = <0xce>;
		phandle = <0xce>;
	};

	qos@ffad0480 {
		compatible = "syscon";
		reg = <0x0 0xffad0480 0x0 0x20>;
		linux,phandle = <0xcf>;
		phandle = <0xcf>;
	};

	qos@ffad0500 {
		compatible = "syscon";
		reg = <0x0 0xffad0500 0x0 0x20>;
		linux,phandle = <0xca>;
		phandle = <0xca>;
	};

	qos@ffad0800 {
		compatible = "syscon";
		reg = <0x0 0xffad0800 0x0 0x20>;
		linux,phandle = <0xd0>;
		phandle = <0xd0>;
	};

	qos@ffad0880 {
		compatible = "syscon";
		reg = <0x0 0xffad0880 0x0 0x20>;
		linux,phandle = <0xd1>;
		phandle = <0xd1>;
	};

	qos@ffad0900 {
		compatible = "syscon";
		reg = <0x0 0xffad0900 0x0 0x20>;
		linux,phandle = <0xd2>;
		phandle = <0xd2>;
	};

	qos@ffae0000 {
		compatible = "syscon";
		reg = <0x0 0xffae0000 0x0 0x20>;
		linux,phandle = <0xd5>;
		phandle = <0xd5>;
	};

	qos@ffaf0000 {
		compatible = "syscon";
		reg = <0x0 0xffaf0000 0x0 0x20>;
		linux,phandle = <0xd3>;
		phandle = <0xd3>;
	};

	qos@ffaf0080 {
		compatible = "syscon";
		reg = <0x0 0xffaf0080 0x0 0x20>;
		linux,phandle = <0xd4>;
		phandle = <0xd4>;
	};

	power-management@ff730000 {
		compatible = "rockchip,rk3288-pmu", "syscon", "simple-mfd";
		reg = <0x0 0xff730000 0x0 0x100>;
		linux,phandle = <0x78>;
		phandle = <0x78>;

		power-controller {
			compatible = "rockchip,rk3288-power-controller";
			#power-domain-cells = <0x1>;
			#address-cells = <0x1>;
			#size-cells = <0x0>;
			linux,phandle = <0xde>;
			phandle = <0xde>;

			pd_vio@9 {
				reg = <0x9>;
				clocks = <0x79 0xca 0x79 0xcd 0x79 0xc8 0x79 0xcc 0x79 0xc5 0x79 0xc6 0x79 0xbe 0x79 0xbf 0x79 0x1d4 0x79 0x1d5 0x79 0x1d6 0x79 0x1d9 0x79 0x1d1 0x79 0x1d2 0x79 0x163 0x79 0x168 0x79 0x167 0x79 0x166 0x79 0x164 0x79 0x165 0x79 0x68 0x79 0x69 0x79 0x6c 0x79 0x6b 0x79 0x6a>;
				pm_qos = <0xca 0xcb 0xcc 0xcd 0xce 0xcf 0xd0 0xd1 0xd2>;
			};

			pd_hevc@11 {
				reg = <0xb>;
				clocks = <0x79 0xcf 0x79 0x6f 0x79 0x70>;
				pm_qos = <0xd3 0xd4>;
			};

			pd_video@12 {
				reg = <0xc>;
				clocks = <0x79 0xd0 0x79 0x1dc>;
				pm_qos = <0xd5>;
			};

			pd_gpu@13 {
				reg = <0xd>;
				clocks = <0x79 0xc0>;
				pm_qos = <0xd6 0xd7>;
			};
		};

		reboot-mode {
			compatible = "syscon-reboot-mode";
			offset = <0x94>;
			mode-normal = <0x5242c300>;
			mode-recovery = <0x5242c303>;
			mode-bootloader = <0x5242c309>;
			mode-loader = <0x5242c301>;
			mode-ums = <0x5242c30c>;
		};
	};

	syscon@ff740000 {
		compatible = "rockchip,rk3288-sgrf", "syscon";
		reg = <0x0 0xff740000 0x0 0x1000>;
		linux,phandle = <0xc2>;
		phandle = <0xc2>;
	};

	clock-controller@ff760000 {
		compatible = "rockchip,rk3288-cru";
		reg = <0x0 0xff760000 0x0 0x1000>;
		rockchip,grf = <0xb6>;
		#clock-cells = <0x1>;
		#reset-cells = <0x1>;
		assigned-clocks = <0x79 0x4 0x79 0x5 0x79 0xd1 0x79 0x1dd 0x79 0x16a 0x79 0xd2 0x79 0x1de 0x79 0x16b>;
		assigned-clock-rates = <0x2367b880 0x1dcd6500 0x11e1a300 0x8f0d180 0x47868c0 0x11e1a300 0x8f0d180 0x47868c0>;
		linux,phandle = <0x79>;
		phandle = <0x79>;
	};

	syscon@ff770000 {
		compatible = "rockchip,rk3288-grf", "syscon", "simple-mfd";
		reg = <0x0 0xff770000 0x0 0x1000>;
		linux,phandle = <0xb6>;
		phandle = <0xb6>;

		edp-phy {
			compatible = "rockchip,rk3288-dp-phy";
			clocks = <0x79 0x68>;
			clock-names = "24m";
			#phy-cells = <0x0>;
			status = "disabled";
			linux,phandle = <0xfb>;
			phandle = <0xfb>;
		};

		io-domains {
			compatible = "rockchip,rk3288-io-voltage-domain";
			status = "okay";
			audio-supply = <0xd8>;
			bb-supply = <0x90>;
			dvp-supply = <0xd9>;
			flash0-supply = <0x91>;
			flash1-supply = <0xbc>;
			gpio30-supply = <0x90>;
			gpio1830-supply = <0x90>;
			lcdc-supply = <0x90>;
			sdcard-supply = <0x84>;
			wifi-supply = <0x8b>;
		};

		usbphy {
			compatible = "rockchip,rk3288-usb-phy";
			#address-cells = <0x1>;
			#size-cells = <0x0>;
			status = "okay";

			usb-phy@320 {
				#phy-cells = <0x0>;
				reg = <0x320>;
				clocks = <0x79 0x5d>;
				clock-names = "phyclk";
				#clock-cells = <0x0>;
				resets = <0x79 0x85>;
				reset-names = "phy-reset";
				linux,phandle = <0xc1>;
				phandle = <0xc1>;
			};

			usb-phy@334 {
				#phy-cells = <0x0>;
				reg = <0x334>;
				clocks = <0x79 0x5e>;
				clock-names = "phyclk";
				#clock-cells = <0x0>;
				linux,phandle = <0xbe>;
				phandle = <0xbe>;
			};

			usb-phy@348 {
				#phy-cells = <0x0>;
				reg = <0x348>;
				clocks = <0x79 0x5f>;
				clock-names = "phyclk";
				#clock-cells = <0x0>;
				resets = <0x79 0x8b>;
				reset-names = "phy-reset";
				linux,phandle = <0xbf>;
				phandle = <0xbf>;
			};
		};
	};

	watchdog@ff800000 {
		compatible = "rockchip,rk3288-wdt", "snps,dw-wdt";
		reg = <0x0 0xff800000 0x0 0x100>;
		clocks = <0x79 0x170>;
		interrupts = <0x0 0x4f 0x4>;
		status = "okay";
	};

	sound@ff8b0000 {
		compatible = "rockchip,rk3288-spdif", "rockchip,rk3066-spdif";
		reg = <0x0 0xff8b0000 0x0 0x10000>;
		#sound-dai-cells = <0x0>;
		clock-names = "hclk", "mclk";
		clocks = <0x79 0x1d0 0x79 0x54>;
		dmas = <0xda 0x3>;
		dma-names = "tx";
		interrupts = <0x0 0x36 0x4>;
		pinctrl-names = "default";
		pinctrl-0 = <0xdb>;
		rockchip,grf = <0xb6>;
		status = "okay";
		linux,phandle = <0x11e>;
		phandle = <0x11e>;
	};

	i2s@ff890000 {
		compatible = "rockchip,rk3288-i2s", "rockchip,rk3066-i2s";
		reg = <0x0 0xff890000 0x0 0x10000>;
		interrupts = <0x0 0x35 0x4>;
		#address-cells = <0x1>;
		#size-cells = <0x0>;
		dmas = <0xda 0x0 0xda 0x1>;
		dma-names = "tx", "rx";
		clock-names = "i2s_hclk", "i2s_clk";
		clocks = <0x79 0x1ce 0x79 0x52>;
		pinctrl-names = "default";
		pinctrl-0 = <0xdc>;
		rockchip,playback-channels = <0x8>;
		rockchip,capture-channels = <0x2>;
		status = "disabled";
	};

	iep@ff90000 {
		compatible = "rockchip,iep";
		iommu_enabled = <0x1>;
		iommus = <0xdd>;
		reg = <0x0 0xff900000 0x0 0x800>;
		interrupts = <0x0 0x11 0x4 0x0>;
		clocks = <0x79 0xca 0x79 0x1d4>;
		clock-names = "aclk_iep", "hclk_iep";
		power-domains = <0xde 0x9>;
		allocator = <0x1>;
		version = <0x1>;
		status = "disabled";
	};

	iommu@ff900800 {
		compatible = "rockchip,iommu";
		reg = <0x0 0xff900800 0x0 0x40>;
		interrupts = <0x0 0x11 0x4 0x0>;
		interrupt-names = "iep_mmu";
		#iommu-cells = <0x0>;
		status = "disabled";
		linux,phandle = <0xdd>;
		phandle = <0xdd>;
	};

	cif@ff950000 {
		compatible = "rockchip,cif";
		reg = <0x0 0xff950000 0x0 0x10000>;
		interrupts = <0x0 0xd 0x4>;
		clocks = <0xdf 0x40 0xe 0x40 0xf 0xe0 0x5 0x0 0x3b>;
		clock-names = "pd_cif0", "aclk_cif0", "hclk_cif0", "cif0_in", "g_pclkin_cif", "cif0_out";
		pinctrl-names = "cif_pin_all";
		pinctrl-0 = <0xe1>;
		gpios-cifpower = <0xa1 0xd 0x0>;
		gpios-dvppower = <0xe2 0xb 0x0>;
		status = "okay";
	};

	cif_isp@ff910000 {
		compatible = "rockchip,rk3288-cif-isp";
		rockchip,grf = <0xb6>;
		reg = <0x0 0xff910000 0x0 0x4000 0x0 0xff968000 0x0 0x4000>;
		reg-names = "register", "csihost-register";
		clocks = <0x79 0xcd 0x79 0x1d5 0x79 0x6b 0x79 0x6c 0x79 0x166 0x79 0x173 0x79 0x7e>;
		clock-names = "aclk_isp", "hclk_isp", "sclk_isp", "sclk_isp_jpe", "pclk_mipi_csi", "pclk_isp_in", "sclk_mipidsi_24m";
		resets = <0x79 0x6e>;
		reset-names = "rst_isp";
		interrupts = <0x0 0xe 0x4>;
		interrupt-names = "cif_isp10_irq";
		power-domains = <0xde 0x9>;
		rockchip,isp,iommu-enable = <0x1>;
		iommus = <0xe3>;
		status = "disabled";
	};

	isp@ff910000 {
		compatible = "rockchip,rk3288-isp", "rockchip,isp";
		reg = <0x0 0xff910000 0x0 0x4000>;
		interrupts = <0x0 0xe 0x4>;
		power-domains = <0xde 0x9>;
		clocks = <0x79 0xcd 0x79 0x1d5 0x79 0x6b 0x79 0x6c 0x79 0x173 0x79 0x7f 0x79 0x7e 0x79 0x7f 0x79 0x166>;
		clock-names = "aclk_isp", "hclk_isp", "clk_isp", "clk_isp_jpe", "pclkin_isp", "clk_cif_out", "clk_mipi_24m", "clk_cif_pll", "hclk_mipiphy1";
		pinctrl-names = "default", "isp_dvp8bit2", "isp_dvp10bit", "isp_dvp12bit", "isp_dvp8bit0", "isp_mipi_fl", "isp_mipi_fl_prefl", "isp_flash_as_gpio", "isp_flash_as_trigger_out";
		pinctrl-0 = <0xe4>;
		pinctrl-1 = <0xe4 0xe1>;
		pinctrl-2 = <0xe4 0xe1 0xe5>;
		pinctrl-3 = <0xe4 0xe1 0xe5 0xe6>;
		pinctrl-4 = <0xe4 0xe7>;
		pinctrl-5 = <0xe4>;
		pinctrl-6 = <0xe4 0xe8>;
		pinctrl-7 = <0xe9>;
		pinctrl-8 = <0xea>;
		rockchip,isp,mipiphy = <0x2>;
		rockchip,isp,cifphy = <0x1>;
		rockchip,isp,mipiphy1,reg = <0xff968000 0x4000>;
		rockchip,grf = <0xb6>;
		rockchip,cru = <0x79>;
		rockchip,gpios = <0xa1 0xd 0x0>;
		rockchip,isp,iommu_enable = <0x1>;
		iommus = <0xe3>;
		status = "disabled";
	};

	iommu@ff914000 {
		compatible = "rockchip,iommu";
		reg = <0x0 0xff914000 0x0 0x100 0x0 0xff915000 0x0 0x100>;
		interrupts = <0x0 0xe 0x4>;
		interrupt-names = "isp_mmu";
		clocks = <0x79 0xcd 0x79 0x1d5>;
		clock-names = "aclk", "hclk";
		rk_iommu,disable_reset_quirk;
		#iommu-cells = <0x0>;
		power-domains = <0xde 0x9>;
		status = "disabled";
		linux,phandle = <0xe3>;
		phandle = <0xe3>;
	};

	rga@ff920000 {
		compatible = "rockchip,rk3288-rga";
		reg = <0x0 0xff920000 0x0 0x180>;
		interrupts = <0x0 0x12 0x4>;
		clocks = <0x79 0xc8 0x79 0x1d6 0x79 0x6a>;
		clock-names = "aclk", "hclk", "sclk";
		power-domains = <0xde 0x9>;
		resets = <0x79 0x69 0x79 0x6c 0x79 0x6d>;
		reset-names = "core", "axi", "ahb";
		status = "okay";
	};

	vop@ff930000 {
		compatible = "rockchip,rk3288-vop";
		reg = <0x0 0xff930000 0x0 0x19c 0x0 0xff931000 0x0 0x1000>;
		reg-names = "regs", "gamma_lut";
		interrupts = <0x0 0xf 0x4>;
		clocks = <0x79 0xc5 0x79 0xbe 0x79 0x1d1>;
		clock-names = "aclk_vop", "dclk_vop", "hclk_vop";
		power-domains = <0xde 0x9>;
		resets = <0x79 0x64 0x79 0x65 0x79 0x66>;
		reset-names = "axi", "ahb", "dclk";
		iommus = <0xeb>;
		status = "okay";

		port {
			#address-cells = <0x1>;
			#size-cells = <0x0>;
			linux,phandle = <0x7e>;
			phandle = <0x7e>;

			endpoint@0 {
				reg = <0x0>;
				remote-endpoint = <0xec>;
				linux,phandle = <0x105>;
				phandle = <0x105>;
			};

			endpoint@1 {
				reg = <0x1>;
				remote-endpoint = <0xed>;
				linux,phandle = <0xfd>;
				phandle = <0xfd>;
			};

			endpoint@2 {
				reg = <0x2>;
				remote-endpoint = <0xee>;
				linux,phandle = <0xf7>;
				phandle = <0xf7>;
			};

			endpoint@3 {
				reg = <0x3>;
				remote-endpoint = <0xef>;
				linux,phandle = <0x101>;
				phandle = <0x101>;
			};

			endpoint@4 {
				reg = <0x4>;
				remote-endpoint = <0xf0>;
				linux,phandle = <0xf9>;
				phandle = <0xf9>;
			};
		};
	};

	iommu@ff930300 {
		compatible = "rockchip,iommu";
		reg = <0x0 0xff930300 0x0 0x100>;
		interrupts = <0x0 0xf 0x4>;
		interrupt-names = "vopb_mmu";
		clocks = <0x79 0xc5 0x79 0x1d1>;
		clock-names = "aclk", "hclk";
		power-domains = <0xde 0x9>;
		#iommu-cells = <0x0>;
		status = "okay";
		linux,phandle = <0xeb>;
		phandle = <0xeb>;
	};

	vop@ff940000 {
		compatible = "rockchip,rk3288-vop";
		reg = <0x0 0xff940000 0x0 0x19c 0x0 0xff941000 0x0 0x1000>;
		reg-names = "regs", "gamma_lut";
		interrupts = <0x0 0x10 0x4>;
		clocks = <0x79 0xc6 0x79 0xbf 0x79 0x1d2>;
		clock-names = "aclk_vop", "dclk_vop", "hclk_vop";
		power-domains = <0xde 0x9>;
		resets = <0x79 0xb0 0x79 0xb1 0x79 0xb2>;
		reset-names = "axi", "ahb", "dclk";
		iommus = <0xf1>;
		status = "okay";

		port {
			#address-cells = <0x1>;
			#size-cells = <0x0>;
			linux,phandle = <0x7d>;
			phandle = <0x7d>;

			endpoint@0 {
				reg = <0x0>;
				remote-endpoint = <0xf2>;
				linux,phandle = <0x106>;
				phandle = <0x106>;
			};

			endpoint@1 {
				reg = <0x1>;
				remote-endpoint = <0xf3>;
				linux,phandle = <0xfe>;
				phandle = <0xfe>;
			};

			endpoint@2 {
				reg = <0x2>;
				remote-endpoint = <0xf4>;
				linux,phandle = <0xf8>;
				phandle = <0xf8>;
			};

			endpoint@3 {
				reg = <0x3>;
				remote-endpoint = <0xf5>;
				linux,phandle = <0x102>;
				phandle = <0x102>;
			};

			endpoint@4 {
				reg = <0x4>;
				remote-endpoint = <0xf6>;
				linux,phandle = <0xfa>;
				phandle = <0xfa>;
			};
		};
	};

	iommu@ff940300 {
		compatible = "rockchip,iommu";
		reg = <0x0 0xff940300 0x0 0x100>;
		interrupts = <0x0 0x10 0x4>;
		interrupt-names = "vopl_mmu";
		clocks = <0x79 0xc6 0x79 0x1d2>;
		clock-names = "aclk", "hclk";
		power-domains = <0xde 0x9>;
		#iommu-cells = <0x0>;
		status = "okay";
		linux,phandle = <0xf1>;
		phandle = <0xf1>;
	};

	dsi@ff960000 {
		compatible = "rockchip,rk3288-mipi-dsi", "snps,dw-mipi-dsi";
		reg = <0x0 0xff960000 0x0 0x4000>;
		interrupts = <0x0 0x13 0x4>;
		clocks = <0x79 0x7e 0x79 0x164>;
		clock-names = "ref", "pclk";
		resets = <0x79 0x73>;
		reset-names = "apb";
		power-domains = <0xde 0x9>;
		rockchip,grf = <0xb6>;
		#address-cells = <0x1>;
		#size-cells = <0x0>;
		status = "disabled";

		ports {
			#address-cells = <0x1>;
			#size-cells = <0x0>;

			port {
				#address-cells = <0x1>;
				#size-cells = <0x0>;

				endpoint@0 {
					reg = <0x0>;
					remote-endpoint = <0xf7>;
					linux,phandle = <0xee>;
					phandle = <0xee>;
				};

				endpoint@1 {
					reg = <0x1>;
					remote-endpoint = <0xf8>;
					linux,phandle = <0xf4>;
					phandle = <0xf4>;
				};
			};
		};
	};

	dsi@ff964000 {
		compatible = "rockchip,rk3288-mipi-dsi", "snps,dw-mipi-dsi";
		reg = <0x0 0xff964000 0x0 0x4000>;
		interrupts = <0x0 0x14 0x4>;
		clocks = <0x79 0x7e 0x79 0x165>;
		clock-names = "ref", "pclk";
		resets = <0x79 0x74>;
		reset-names = "apb";
		power-domains = <0xde 0x9>;
		rockchip,grf = <0xb6>;
		#address-cells = <0x1>;
		#size-cells = <0x0>;
		status = "disabled";

		ports {
			#address-cells = <0x1>;
			#size-cells = <0x0>;

			port {
				#address-cells = <0x1>;
				#size-cells = <0x0>;

				endpoint@0 {
					reg = <0x0>;
					remote-endpoint = <0xf9>;
					linux,phandle = <0xf0>;
					phandle = <0xf0>;
				};

				endpoint@1 {
					reg = <0x1>;
					remote-endpoint = <0xfa>;
					linux,phandle = <0xf6>;
					phandle = <0xf6>;
				};
			};
		};
	};

	dp@ff970000 {
		compatible = "rockchip,rk3288-dp";
		reg = <0x0 0xff970000 0x0 0x4000>;
		interrupts = <0x0 0x62 0x4>;
		clocks = <0x79 0x69 0x79 0x163>;
		clock-names = "dp", "pclk";
		power-domains = <0xde 0x9>;
		phys = <0xfb>;
		phy-names = "dp";
		resets = <0x79 0x6f>;
		reset-names = "dp";
		rockchip,grf = <0xb6>;
		status = "disabled";
		vcc-supply = <0xfc>;
		vccio-supply = <0x8b>;
		force-hpd;

		ports {
			#address-cells = <0x1>;
			#size-cells = <0x0>;

			port@0 {
				reg = <0x0>;
				#address-cells = <0x1>;
				#size-cells = <0x0>;

				endpoint@0 {
					reg = <0x0>;
					remote-endpoint = <0xfd>;
					linux,phandle = <0xed>;
					phandle = <0xed>;
				};

				endpoint@1 {
					reg = <0x1>;
					remote-endpoint = <0xfe>;
					linux,phandle = <0xf3>;
					phandle = <0xf3>;
				};
			};

			port@1 {
				reg = <0x1>;
				#address-cells = <0x1>;
				#size-cells = <0x0>;

				endpoint {
					reg = <0x0>;
					remote-endpoint = <0xff>;
					linux,phandle = <0x115>;
					phandle = <0x115>;
				};
			};
		};
	};

	lvds@ff96c000 {
		compatible = "rockchip,rk3288-lvds";
		reg = <0x0 0xff96c000 0x0 0x4000>;
		clocks = <0x79 0x167>;
		clock-names = "pclk_lvds";
		pinctrl-names = "lcdc";
		pinctrl-0 = <0x100>;
		power-domains = <0xde 0x9>;
		rockchip,grf = <0xb6>;
		status = "disabled";

		ports {
			#address-cells = <0x1>;
			#size-cells = <0x0>;

			port@0 {
				reg = <0x0>;
				#address-cells = <0x1>;
				#size-cells = <0x0>;

				endpoint@0 {
					reg = <0x0>;
					remote-endpoint = <0x101>;
					linux,phandle = <0xef>;
					phandle = <0xef>;
				};

				endpoint@1 {
					reg = <0x1>;
					remote-endpoint = <0x102>;
					linux,phandle = <0xf5>;
					phandle = <0xf5>;
				};
			};
		};
	};

	hdmi@ff980000 {
		compatible = "rockchip,rk3288-dw-hdmi";
		reg = <0x0 0xff980000 0x0 0x20000>;
		reg-io-width = <0x4>;
		rockchip,grf = <0xb6>;
		interrupts = <0x0 0x67 0x4>;
		clocks = <0x79 0x168 0x79 0x6d>;
		clock-names = "iahb", "isfr";
		pinctrl-names = "default", "sleep";
		pinctrl-0 = <0x103>;
		pinctrl-1 = <0x104>;
		power-domains = <0xde 0x9>;
		status = "okay";

		ports {

			port {
				#address-cells = <0x1>;
				#size-cells = <0x0>;

				endpoint@0 {
					reg = <0x0>;
					remote-endpoint = <0x105>;
					linux,phandle = <0xec>;
					phandle = <0xec>;
				};

				endpoint@1 {
					reg = <0x1>;
					remote-endpoint = <0x106>;
					linux,phandle = <0xf2>;
					phandle = <0xf2>;
				};
			};
		};
	};

	video-codec@ff9a0000 {
		compatible = "rockchip,rk3288-vpu";
		reg = <0x0 0xff9a0000 0x0 0x800>;
		interrupts = <0x0 0x9 0x4 0x0 0xa 0x4>;
		interrupt-names = "vepu", "vdpu";
		clocks = <0x79 0xd0 0x79 0x1dc>;
		clock-names = "aclk", "hclk";
		power-domains = <0xde 0xc>;
		iommus = <0x107>;
		assigned-clocks = <0x79 0xd0>;
		assigned-clock-rates = <0x17d78400>;
		status = "disabled";
	};

	vpu-service@ff9a0000 {
		compatible = "rockchip,vpu_service";
		reg = <0x0 0xff9a0000 0x0 0x800>;
		interrupts = <0x0 0x9 0x4 0x0 0xa 0x4>;
		interrupt-names = "irq_enc", "irq_dec";
		clocks = <0x79 0xd0 0x79 0x1dc>;
		clock-names = "aclk_vcodec", "hclk_vcodec";
		power-domains = <0xde 0xc>;
		rockchip,grf = <0xb6>;
		resets = <0x79 0x70 0x79 0x71>;
		reset-names = "video_a", "video_h";
		iommus = <0x107>;
		iommu_enabled = <0x1>;
		status = "okay";
		allocator = <0x1>;
	};

	iommu@ff9a0800 {
		compatible = "rockchip,iommu";
		reg = <0x0 0xff9a0800 0x0 0x100>;
		interrupts = <0x0 0xb 0x4>;
		interrupt-names = "vpu_mmu";
		clocks = <0x79 0xd0 0x79 0x1dc>;
		clock-names = "aclk", "hclk";
		power-domains = <0xde 0xc>;
		#iommu-cells = <0x0>;
		linux,phandle = <0x107>;
		phandle = <0x107>;
	};

	hevc-service@ff9c0000 {
		compatible = "rockchip,hevc_service";
		reg = <0x0 0xff9c0000 0x0 0x400>;
		interrupts = <0x0 0xc 0x4>;
		interrupt-names = "irq_dec";
		clocks = <0x79 0xcf 0x79 0x1db 0x79 0x70 0x79 0x6f>;
		clock-names = "aclk_vcodec", "hclk_vcodec", "clk_core", "clk_cabac";
		assigned-clocks = <0x79 0xcf 0x79 0x1db 0x79 0x70 0x79 0x6f>;
		assigned-clock-rates = <0x17d78400 0x5f5e100 0x11e1a300 0x11e1a300>;
		resets = <0x79 0x9a>;
		reset-names = "video";
		power-domains = <0xde 0xb>;
		rockchip,grf = <0xb6>;
		iommus = <0x108>;
		iommu_enabled = <0x1>;
		status = "okay";
		allocator = <0x1>;
	};

	iommu@ff9c0440 {
		compatible = "rockchip,iommu";
		reg = <0x0 0xff9c0440 0x0 0x40 0x0 0xff9c0480 0x0 0x40>;
		interrupts = <0x0 0x6f 0x4>;
		interrupt-names = "hevc_mmu";
		clocks = <0x79 0xcf 0x79 0x1db 0x79 0x70 0x79 0x6f>;
		clock-names = "aclk", "hclk", "clk_core", "clk_cabac";
		power-domains = <0xde 0xb>;
		#iommu-cells = <0x0>;
		linux,phandle = <0x108>;
		phandle = <0x108>;
	};

	gpu@ffa30000 {
		compatible = "arm,malit764", "arm,malit76x", "arm,malit7xx", "arm,mali-midgard";
		reg = <0x0 0xffa30000 0x0 0x10000>;
		interrupts = <0x0 0x6 0x4 0x0 0x7 0x4 0x0 0x8 0x4>;
		interrupt-names = "JOB", "MMU", "GPU";
		clocks = <0x79 0xc0>;
		clock-names = "clk_mali";
		operating-points-v2 = <0x109>;
		#cooling-cells = <0x2>;
		power-domains = <0xde 0xd>;
		status = "okay";
		upthreshold = <0x4b>;
		downdifferential = <0xa>;
		mali-supply = <0x10a>;
		linux,phandle = <0xb3>;
		phandle = <0xb3>;

		power_model {
			compatible = "arm,mali-simple-power-model";
			voltage = <0x3b6>;
			frequency = <0x1f4>;
			static-power = <0x12c>;
			dynamic-power = <0x18c>;
			ts = <0x7d00 0x125c 0xffffffb0 0x2>;
			thermal-zone = "gpu-thermal";
		};
	};

	opp-table1 {
		compatible = "operating-points-v2";
		linux,phandle = <0x109>;
		phandle = <0x109>;

		opp-100000000 {
			opp-hz = <0x0 0x5f5e100>;
			opp-microvolt = <0xe7ef0>;
		};

		opp-200000000 {
			opp-hz = <0x0 0xbebc200>;
			opp-microvolt = <0xe7ef0>;
		};

		opp-300000000 {
			opp-hz = <0x0 0x11e1a300>;
			opp-microvolt = <0xf4240>;
		};

		opp-400000000 {
			opp-hz = <0x0 0x17d78400>;
			opp-microvolt = <0x10c8e0>;
		};

		opp-600000000 {
			opp-hz = <0x0 0x23c34600>;
			opp-microvolt = <0x1312d0>;
		};
	};

	syscon@ffac0000 {
		compatible = "rockchip,rk3288-noc", "syscon";
		reg = <0x0 0xffac0000 0x0 0x2000>;
		linux,phandle = <0xc3>;
		phandle = <0xc3>;
	};

	nocp-core@ffac0400 {
		compatible = "rockchip,rk3288-nocp";
		reg = <0x0 0xffac0400 0x0 0x400>;
	};

	nocp-gpu@ffac0800 {
		compatible = "rockchip,rk3288-nocp";
		reg = <0x0 0xffac0800 0x0 0x400>;
	};

	nocp-peri@ffac0c00 {
		compatible = "rockchip,rk3288-nocp";
		reg = <0x0 0xffac0c00 0x0 0x400>;
	};

	nocp-vpu@ffac1000 {
		compatible = "rockchip,rk3288-nocp";
		reg = <0x0 0xffac1000 0x0 0x400>;
	};

	nocp-vio0@ffac1400 {
		compatible = "rockchip,rk3288-nocp";
		reg = <0x0 0xffac1400 0x0 0x400>;
	};

	nocp-vio1@ffac1800 {
		compatible = "rockchip,rk3288-nocp";
		reg = <0x0 0xffac1800 0x0 0x400>;
	};

	nocp-vio2@ffac1c00 {
		compatible = "rockchip,rk3288-nocp";
		reg = <0x0 0xffac1c00 0x0 0x400>;
	};

	efuse@ffb40000 {
		compatible = "rockchip,rockchip-efuse";
		reg = <0x0 0xffb40000 0x0 0x20>;
		#address-cells = <0x1>;
		#size-cells = <0x1>;
		clocks = <0x79 0x171>;
		clock-names = "pclk_efuse";

		id@7 {
			reg = <0x7 0x10>;
		};

		cpu_leakage@17 {
			reg = <0x17 0x1>;
			linux,phandle = <0x7c>;
			phandle = <0x7c>;
		};
	};

	interrupt-controller@ffc01000 {
		compatible = "arm,gic-400";
		interrupt-controller;
		#interrupt-cells = <0x3>;
		#address-cells = <0x0>;
		reg = <0x0 0xffc01000 0x0 0x1000 0x0 0xffc02000 0x0 0x2000 0x0 0xffc04000 0x0 0x2000 0x0 0xffc06000 0x0 0x2000>;
		interrupts = <0x1 0x9 0xf04>;
		linux,phandle = <0x1>;
		phandle = <0x1>;
	};

	pinctrl {
		compatible = "rockchip,rk3288-pinctrl";
		rockchip,grf = <0xb6>;
		rockchip,pmu = <0x78>;
		#address-cells = <0x2>;
		#size-cells = <0x2>;
		ranges;

		gpio0@ff750000 {
			compatible = "rockchip,gpio-bank";
			reg = <0x0 0xff750000 0x0 0x100>;
			interrupts = <0x0 0x51 0x4>;
			clocks = <0x79 0x140>;
			gpio-controller;
			#gpio-cells = <0x2>;
			interrupt-controller;
			#interrupt-cells = <0x2>;
			linux,phandle = <0xe2>;
			phandle = <0xe2>;
		};

		gpio1@ff780000 {
			compatible = "rockchip,gpio-bank";
			reg = <0x0 0xff780000 0x0 0x100>;
			interrupts = <0x0 0x52 0x4>;
			clocks = <0x79 0x141>;
			gpio-controller;
			#gpio-cells = <0x2>;
			interrupt-controller;
			#interrupt-cells = <0x2>;
		};

		gpio2@ff790000 {
			compatible = "rockchip,gpio-bank";
			reg = <0x0 0xff790000 0x0 0x100>;
			interrupts = <0x0 0x53 0x4>;
			clocks = <0x79 0x142>;
			gpio-controller;
			#gpio-cells = <0x2>;
			interrupt-controller;
			#interrupt-cells = <0x2>;
			linux,phandle = <0x127>;
			phandle = <0x127>;
		};

		gpio3@ff7a0000 {
			compatible = "rockchip,gpio-bank";
			reg = <0x0 0xff7a0000 0x0 0x100>;
			interrupts = <0x0 0x54 0x4>;
			clocks = <0x79 0x143>;
			gpio-controller;
			#gpio-cells = <0x2>;
			interrupt-controller;
			#interrupt-cells = <0x2>;
		};

		gpio4@ff7b0000 {
			compatible = "rockchip,gpio-bank";
			reg = <0x0 0xff7b0000 0x0 0x100>;
			interrupts = <0x0 0x55 0x4>;
			clocks = <0x79 0x144>;
			gpio-controller;
			#gpio-cells = <0x2>;
			interrupt-controller;
			#interrupt-cells = <0x2>;
			linux,phandle = <0xbd>;
			phandle = <0xbd>;
		};

		gpio5@ff7c0000 {
			compatible = "rockchip,gpio-bank";
			reg = <0x0 0xff7c0000 0x0 0x100>;
			interrupts = <0x0 0x56 0x4>;
			clocks = <0x79 0x145>;
			gpio-controller;
			#gpio-cells = <0x2>;
			interrupt-controller;
			#interrupt-cells = <0x2>;
			linux,phandle = <0xa7>;
			phandle = <0xa7>;
		};

		gpio6@ff7d0000 {
			compatible = "rockchip,gpio-bank";
			reg = <0x0 0xff7d0000 0x0 0x100>;
			interrupts = <0x0 0x57 0x4>;
			clocks = <0x79 0x146>;
			gpio-controller;
			#gpio-cells = <0x2>;
			interrupt-controller;
			#interrupt-cells = <0x2>;
		};

		gpio7@ff7e0000 {
			compatible = "rockchip,gpio-bank";
			reg = <0x0 0xff7e0000 0x0 0x100>;
			interrupts = <0x0 0x58 0x4>;
			clocks = <0x79 0x147>;
			gpio-controller;
			#gpio-cells = <0x2>;
			interrupt-controller;
			#interrupt-cells = <0x2>;
			linux,phandle = <0xa1>;
			phandle = <0xa1>;
		};

		gpio8@ff7f0000 {
			compatible = "rockchip,gpio-bank";
			reg = <0x0 0xff7f0000 0x0 0x100>;
			interrupts = <0x0 0x59 0x4>;
			clocks = <0x79 0x148>;
			gpio-controller;
			#gpio-cells = <0x2>;
			interrupt-controller;
			#interrupt-cells = <0x2>;
			linux,phandle = <0x119>;
			phandle = <0x119>;
		};

		hdmi {

			hdmi-gpio {
				rockchip,pins = <0x7 0x13 0x0 0x10b 0x7 0x14 0x0 0x10b>;
				linux,phandle = <0x104>;
				phandle = <0x104>;
			};

			hdmi-ddc {
				rockchip,pins = <0x7 0x13 0x2 0x10b 0x7 0x14 0x2 0x10b>;
				linux,phandle = <0x103>;
				phandle = <0x103>;
			};
		};

		pcfg-pull-up {
			bias-pull-up;
			linux,phandle = <0x10c>;
			phandle = <0x10c>;
		};

		pcfg-pull-down {
			bias-pull-down;
			linux,phandle = <0x10d>;
			phandle = <0x10d>;
		};

		pcfg-pull-none {
			bias-disable;
			linux,phandle = <0x10b>;
			phandle = <0x10b>;
		};

		pcfg-pull-none-12ma {
			bias-disable;
			drive-strength = <0xc>;
			linux,phandle = <0x110>;
			phandle = <0x110>;
		};

		sleep {

			global-pwroff {
				rockchip,pins = <0x0 0x0 0x1 0x10b>;
			};

			ddrio-pwroff {
				rockchip,pins = <0x0 0x1 0x1 0x10b>;
			};

			ddr0-retention {
				rockchip,pins = <0x0 0x2 0x1 0x10c>;
			};

			ddr1-retention {
				rockchip,pins = <0x0 0x3 0x1 0x10c>;
			};
		};

		edp {

			edp-hpd {
				rockchip,pins = <0x7 0xb 0x2 0x10d>;
			};
		};

		i2c0 {

			i2c0-xfer {
				rockchip,pins = <0x0 0xf 0x1 0x10b 0x0 0x10 0x1 0x10b>;
				linux,phandle = <0xa0>;
				phandle = <0xa0>;
			};
		};

		i2c1 {

			i2c1-xfer {
				rockchip,pins = <0x8 0x4 0x1 0x10b 0x8 0x5 0x1 0x10b>;
				linux,phandle = <0xa6>;
				phandle = <0xa6>;
			};
		};

		i2c2 {

			i2c2-xfer {
				rockchip,pins = <0x6 0x9 0x1 0x10b 0x6 0xa 0x1 0x10b>;
				linux,phandle = <0xc5>;
				phandle = <0xc5>;
			};
		};

		i2c3 {

			i2c3-xfer {
				rockchip,pins = <0x2 0x10 0x1 0x10b 0x2 0x11 0x1 0x10b>;
				linux,phandle = <0xa8>;
				phandle = <0xa8>;
			};
		};

		i2c4 {

			i2c4-xfer {
				rockchip,pins = <0x7 0x11 0x1 0x10b 0x7 0x12 0x1 0x10b>;
				linux,phandle = <0xa9>;
				phandle = <0xa9>;
			};
		};

		i2c5 {

			i2c5-xfer {
				rockchip,pins = <0x7 0x13 0x1 0x10b 0x7 0x14 0x1 0x10b>;
				linux,phandle = <0xaa>;
				phandle = <0xaa>;
			};
		};

		i2s0 {

			i2s0-bus {
				rockchip,pins = <0x6 0x0 0x1 0x10b 0x6 0x1 0x1 0x10b 0x6 0x2 0x1 0x10b 0x6 0x3 0x1 0x10b 0x6 0x4 0x1 0x10b>;
				linux,phandle = <0xdc>;
				phandle = <0xdc>;
			};

			i2s0-mclk {
				rockchip,pins = <0x6 0x8 0x1 0x10b>;
			};
		};

		lcdc {

			lcdc-ctl {
				rockchip,pins = <0x1 0x18 0x1 0x10b 0x1 0x19 0x1 0x10b 0x1 0x1a 0x1 0x10b 0x1 0x1b 0x1 0x10b>;
				linux,phandle = <0x100>;
				phandle = <0x100>;
			};
		};

		sdmmc {

			sdmmc-clk {
				rockchip,pins = <0x6 0x14 0x1 0x10e>;
				linux,phandle = <0x7f>;
				phandle = <0x7f>;
			};

			sdmmc-cmd {
				rockchip,pins = <0x6 0x15 0x1 0x10f>;
				linux,phandle = <0x80>;
				phandle = <0x80>;
			};

			sdmmc-cd {
				rockchip,pins = <0x6 0x16 0x1 0x10c>;
				linux,phandle = <0x81>;
				phandle = <0x81>;
			};

			sdmmc-bus1 {
				rockchip,pins = <0x6 0x10 0x1 0x10c>;
			};

			sdmmc-bus4 {
				rockchip,pins = <0x6 0x10 0x1 0x10f 0x6 0x11 0x1 0x10f 0x6 0x12 0x1 0x10f 0x6 0x13 0x1 0x10f>;
				linux,phandle = <0x82>;
				phandle = <0x82>;
			};

			sdmmc-pwr {
				rockchip,pins = <0x7 0xb 0x0 0x10b>;
				linux,phandle = <0x120>;
				phandle = <0x120>;
			};
		};

		sdio0 {

			sdio0-bus1 {
				rockchip,pins = <0x4 0x14 0x1 0x10c>;
			};

			sdio0-bus4 {
				rockchip,pins = <0x4 0x14 0x1 0x10c 0x4 0x15 0x1 0x10c 0x4 0x16 0x1 0x10c 0x4 0x17 0x1 0x10c>;
				linux,phandle = <0x86>;
				phandle = <0x86>;
			};

			sdio0-cmd {
				rockchip,pins = <0x4 0x18 0x1 0x10c>;
				linux,phandle = <0x87>;
				phandle = <0x87>;
			};

			sdio0-clk {
				rockchip,pins = <0x4 0x19 0x1 0x10b>;
				linux,phandle = <0x88>;
				phandle = <0x88>;
			};

			sdio0-cd {
				rockchip,pins = <0x4 0x1a 0x1 0x10c>;
			};

			sdio0-wp {
				rockchip,pins = <0x4 0x1b 0x1 0x10c>;
			};

			sdio0-pwr {
				rockchip,pins = <0x4 0x1c 0x1 0x10c>;
			};

			sdio0-bkpwr {
				rockchip,pins = <0x4 0x1d 0x1 0x10c>;
			};

			sdio0-int {
				rockchip,pins = <0x4 0x1e 0x1 0x10c>;
				linux,phandle = <0x89>;
				phandle = <0x89>;
			};
		};

		sdio1 {

			sdio1-bus1 {
				rockchip,pins = <0x3 0x18 0x4 0x10c>;
			};

			sdio1-bus4 {
				rockchip,pins = <0x3 0x18 0x4 0x10c 0x3 0x19 0x4 0x10c 0x3 0x1a 0x4 0x10c 0x3 0x1b 0x4 0x10c>;
			};

			sdio1-cd {
				rockchip,pins = <0x3 0x1c 0x4 0x10c>;
			};

			sdio1-wp {
				rockchip,pins = <0x3 0x1d 0x4 0x10c>;
			};

			sdio1-bkpwr {
				rockchip,pins = <0x3 0x1e 0x4 0x10c>;
			};

			sdio1-int {
				rockchip,pins = <0x3 0x1f 0x4 0x10c>;
			};

			sdio1-cmd {
				rockchip,pins = <0x4 0x6 0x4 0x10c>;
			};

			sdio1-clk {
				rockchip,pins = <0x4 0x7 0x4 0x10b>;
			};

			sdio1-pwr {
				rockchip,pins = <0x4 0x9 0x4 0x10c>;
			};
		};

		emmc {

			emmc-clk {
				rockchip,pins = <0x3 0x12 0x2 0x10b>;
				linux,phandle = <0x8c>;
				phandle = <0x8c>;
			};

			emmc-cmd {
				rockchip,pins = <0x3 0x10 0x2 0x10c>;
				linux,phandle = <0x8d>;
				phandle = <0x8d>;
			};

			emmc-pwr {
				rockchip,pins = <0x3 0x9 0x2 0x10c>;
				linux,phandle = <0x8e>;
				phandle = <0x8e>;
			};

			emmc-bus1 {
				rockchip,pins = <0x3 0x0 0x2 0x10c>;
			};

			emmc-bus4 {
				rockchip,pins = <0x3 0x0 0x2 0x10c 0x3 0x1 0x2 0x10c 0x3 0x2 0x2 0x10c 0x3 0x3 0x2 0x10c>;
			};

			emmc-bus8 {
				rockchip,pins = <0x3 0x0 0x2 0x10c 0x3 0x1 0x2 0x10c 0x3 0x2 0x2 0x10c 0x3 0x3 0x2 0x10c 0x3 0x4 0x2 0x10c 0x3 0x5 0x2 0x10c 0x3 0x6 0x2 0x10c 0x3 0x7 0x2 0x10c>;
				linux,phandle = <0x8f>;
				phandle = <0x8f>;
			};
		};

		spi0 {

			spi0-clk {
				rockchip,pins = <0x5 0xc 0x1 0x10c>;
				linux,phandle = <0x93>;
				phandle = <0x93>;
			};

			spi0-cs0 {
				rockchip,pins = <0x5 0xd 0x1 0x10c>;
				linux,phandle = <0x94>;
				phandle = <0x94>;
			};

			spi0-tx {
				rockchip,pins = <0x5 0xe 0x1 0x10c>;
				linux,phandle = <0x95>;
				phandle = <0x95>;
			};

			spi0-rx {
				rockchip,pins = <0x5 0xf 0x1 0x10c>;
				linux,phandle = <0x96>;
				phandle = <0x96>;
			};

			spi0-cs1 {
				rockchip,pins = <0x5 0x10 0x1 0x10c>;
				linux,phandle = <0x97>;
				phandle = <0x97>;
			};
		};

		spi1 {

			spi1-clk {
				rockchip,pins = <0x7 0xc 0x2 0x10c>;
				linux,phandle = <0x98>;
				phandle = <0x98>;
			};

			spi1-cs0 {
				rockchip,pins = <0x7 0xd 0x2 0x10c>;
				linux,phandle = <0x9b>;
				phandle = <0x9b>;
			};

			spi1-rx {
				rockchip,pins = <0x7 0xe 0x2 0x10c>;
				linux,phandle = <0x9a>;
				phandle = <0x9a>;
			};

			spi1-tx {
				rockchip,pins = <0x7 0xf 0x2 0x10c>;
				linux,phandle = <0x99>;
				phandle = <0x99>;
			};
		};

		spi2 {

			spi2-cs1 {
				rockchip,pins = <0x8 0x3 0x1 0x10c>;
			};

			spi2-clk {
				rockchip,pins = <0x8 0x6 0x1 0x10c>;
				linux,phandle = <0x9c>;
				phandle = <0x9c>;
			};

			spi2-cs0 {
				rockchip,pins = <0x8 0x7 0x1 0x10c>;
				linux,phandle = <0x9f>;
				phandle = <0x9f>;
			};

			spi2-rx {
				rockchip,pins = <0x8 0x8 0x1 0x10c>;
				linux,phandle = <0x9e>;
				phandle = <0x9e>;
			};

			spi2-tx {
				rockchip,pins = <0x8 0x9 0x1 0x10c>;
				linux,phandle = <0x9d>;
				phandle = <0x9d>;
			};
		};

		uart0 {

			uart0-xfer {
				rockchip,pins = <0x4 0x10 0x1 0x10c 0x4 0x11 0x1 0x10b>;
				linux,phandle = <0xab>;
				phandle = <0xab>;
			};

			uart0-cts {
				rockchip,pins = <0x4 0x12 0x1 0x10c>;
				linux,phandle = <0xac>;
				phandle = <0xac>;
			};

			uart0-rts {
				rockchip,pins = <0x4 0x13 0x1 0x10b>;
				linux,phandle = <0x125>;
				phandle = <0x125>;
			};
		};

		uart1 {

			uart1-xfer {
				rockchip,pins = <0x5 0x8 0x1 0x10c 0x5 0x9 0x1 0x10b>;
				linux,phandle = <0xad>;
				phandle = <0xad>;
			};

			uart1-cts {
				rockchip,pins = <0x5 0xa 0x1 0x10c>;
			};

			uart1-rts {
				rockchip,pins = <0x5 0xb 0x1 0x10b>;
			};
		};

		uart2 {

			uart2-xfer {
				rockchip,pins = <0x7 0x16 0x1 0x10c 0x7 0x17 0x1 0x10b>;
				linux,phandle = <0xae>;
				phandle = <0xae>;
			};
		};

		uart3 {

			uart3-xfer {
				rockchip,pins = <0x7 0x7 0x1 0x10c 0x7 0x8 0x1 0x10b>;
				linux,phandle = <0xaf>;
				phandle = <0xaf>;
			};

			uart3-cts {
				rockchip,pins = <0x7 0x9 0x1 0x10c>;
			};

			uart3-rts {
				rockchip,pins = <0x7 0xa 0x1 0x10b>;
			};
		};

		uart4 {

			uart4-xfer {
				rockchip,pins = <0x5 0xc 0x3 0x10c 0x5 0xd 0x3 0x10b>;
				linux,phandle = <0xb0>;
				phandle = <0xb0>;
			};

			uart4-cts {
				rockchip,pins = <0x5 0xe 0x3 0x10c>;
			};

			uart4-rts {
				rockchip,pins = <0x5 0xf 0x3 0x10b>;
			};
		};

		tsadc {

			otp-gpio {
				rockchip,pins = <0x0 0xa 0x0 0x10b>;
				linux,phandle = <0xb4>;
				phandle = <0xb4>;
			};

			otp-out {
				rockchip,pins = <0x0 0xa 0x1 0x10b>;
				linux,phandle = <0xb5>;
				phandle = <0xb5>;
			};
		};

		pwm0 {

			pwm0-pin {
				rockchip,pins = <0x7 0x0 0x1 0x10b>;
				linux,phandle = <0xc6>;
				phandle = <0xc6>;
			};
		};

		pwm1 {

			pwm1-pin {
				rockchip,pins = <0x7 0x1 0x1 0x10b>;
				linux,phandle = <0xc7>;
				phandle = <0xc7>;
			};
		};

		pwm2 {

			pwm2-pin {
				rockchip,pins = <0x7 0x16 0x3 0x10b>;
				linux,phandle = <0xc8>;
				phandle = <0xc8>;
			};
		};

		pwm3 {

			pwm3-pin {
				rockchip,pins = <0x7 0x17 0x3 0x10b>;
				linux,phandle = <0xc9>;
				phandle = <0xc9>;
			};
		};

		gmac {

			rgmii-pins {
				rockchip,pins = <0x3 0x1e 0x3 0x10b 0x3 0x1f 0x3 0x10b 0x3 0x1a 0x3 0x10b 0x3 0x1b 0x3 0x10b 0x3 0x1c 0x3 0x110 0x3 0x1d 0x3 0x110 0x3 0x18 0x3 0x110 0x3 0x19 0x3 0x110 0x4 0x0 0x3 0x10b 0x4 0x5 0x3 0x10b 0x4 0x6 0x3 0x10b 0x4 0x9 0x3 0x110 0x4 0x4 0x3 0x110 0x4 0x1 0x3 0x10b 0x4 0x3 0x3 0x10b>;
				linux,phandle = <0xb8>;
				phandle = <0xb8>;
			};

			rmii-pins {
				rockchip,pins = <0x3 0x1e 0x3 0x10b 0x3 0x1f 0x3 0x10b 0x3 0x1c 0x3 0x10b 0x3 0x1d 0x3 0x10b 0x4 0x0 0x3 0x10b 0x4 0x5 0x3 0x10b 0x4 0x4 0x3 0x10b 0x4 0x1 0x3 0x10b 0x4 0x2 0x3 0x10b 0x4 0x3 0x3 0x10b>;
			};

			phy-int {
				rockchip,pins = <0x0 0x9 0x0 0x10c>;
				linux,phandle = <0xbb>;
				phandle = <0xbb>;
			};

			phy-pmeb {
				rockchip,pins = <0x0 0x8 0x0 0x10c>;
				linux,phandle = <0xba>;
				phandle = <0xba>;
			};

			phy-rst {
				rockchip,pins = <0x4 0x8 0x0 0x111>;
				linux,phandle = <0xb9>;
				phandle = <0xb9>;
			};
		};

		spdif {

			spdif-tx {
				rockchip,pins = <0x6 0xb 0x1 0x10b>;
				linux,phandle = <0xdb>;
				phandle = <0xdb>;
			};
		};

		cif {

			cif-dvp-d2d9 {
				rockchip,pins = <0x2 0x0 0x1 0x10b 0x2 0x1 0x1 0x10b 0x2 0x2 0x1 0x10b 0x2 0x3 0x1 0x10b 0x2 0x4 0x1 0x10b 0x2 0x5 0x1 0x10b 0x2 0x6 0x1 0x10b 0x2 0x7 0x1 0x10b 0x2 0x8 0x1 0x10b 0x2 0x9 0x1 0x10b 0x2 0xb 0x1 0x10b>;
			};
		};

		isp_pin {

			isp-mipi {
				rockchip,pins = <0x2 0xb 0x1 0x10b>;
				linux,phandle = <0xe4>;
				phandle = <0xe4>;
			};

			isp-d2d9 {
				rockchip,pins = <0x2 0x0 0x1 0x10b 0x2 0x1 0x1 0x10b 0x2 0x2 0x1 0x10b 0x2 0x3 0x1 0x10b 0x2 0x4 0x1 0x10b 0x2 0x5 0x1 0x10b 0x2 0x6 0x1 0x10b 0x2 0x7 0x1 0x10b 0x2 0x8 0x1 0x10b 0x2 0x9 0x1 0x10b 0x2 0xa 0x1 0x10b 0x2 0xb 0x1 0x10b>;
				linux,phandle = <0xe1>;
				phandle = <0xe1>;
			};

			isp-d0d1 {
				rockchip,pins = <0x2 0xc 0x1 0x10b 0x2 0xd 0x1 0x10b>;
				linux,phandle = <0xe5>;
				phandle = <0xe5>;
			};

			isp-d10d11 {
				rockchip,pins = <0x2 0xe 0x1 0x10b 0x2 0xf 0x1 0x10b>;
				linux,phandle = <0xe6>;
				phandle = <0xe6>;
			};

			isp-d0d7 {
				rockchip,pins = <0x2 0xc 0x1 0x10b 0x2 0xd 0x1 0x10b 0x2 0x0 0x1 0x10b 0x2 0x1 0x1 0x10b 0x2 0x2 0x1 0x10b 0x2 0x3 0x1 0x10b 0x2 0x4 0x1 0x10b 0x2 0x5 0x1 0x10b>;
				linux,phandle = <0xe7>;
				phandle = <0xe7>;
			};

			isp-shutter {
				rockchip,pins = <0x7 0xc 0x2 0x10b 0x7 0xf 0x2 0x10b>;
			};

			isp-flash-trigger {
				rockchip,pins = <0x7 0xd 0x2 0x10b>;
				linux,phandle = <0xea>;
				phandle = <0xea>;
			};

			isp-prelight {
				rockchip,pins = <0x7 0xe 0x2 0x10b>;
				linux,phandle = <0xe8>;
				phandle = <0xe8>;
			};

			isp-flash-trigger-as-gpio {
				rockchip,pins = <0x7 0xd 0x2 0x10b>;
				linux,phandle = <0xe9>;
				phandle = <0xe9>;
			};
		};

		pcfg-output-high {
			output-high;
			linux,phandle = <0x111>;
			phandle = <0x111>;
		};

		pcfg-output-low {
			output-low;
			linux,phandle = <0x112>;
			phandle = <0x112>;
		};

		pcfg-pull-none-drv-8ma {
			drive-strength = <0x8>;
			linux,phandle = <0x10e>;
			phandle = <0x10e>;
		};

		pcfg-pull-up-drv-8ma {
			bias-pull-up;
			drive-strength = <0x8>;
			linux,phandle = <0x10f>;
			phandle = <0x10f>;
		};

		act8846 {

			pwr-hold {
				rockchip,pins = <0x0 0x1 0x0 0x111>;
				linux,phandle = <0xa4>;
				phandle = <0xa4>;
			};

			pmic-vsel {
				rockchip,pins = <0x7 0xe 0x0 0x112>;
				linux,phandle = <0xa3>;
				phandle = <0xa3>;
			};
		};

		dvp {

			dvp-pwr {
				rockchip,pins = <0x0 0xb 0x0 0x10b>;
				linux,phandle = <0x124>;
				phandle = <0x124>;
			};
		};

		hym8563 {

			rtc-int {
				rockchip,pins = <0x7 0x4 0x0 0x10c>;
				linux,phandle = <0xa2>;
				phandle = <0xa2>;
			};
		};

		keys {

			pwr-key {
				rockchip,pins = <0x0 0x5 0x0 0x10c>;
				linux,phandle = <0x118>;
				phandle = <0x118>;
			};
		};

		leds {

			power-led {
				rockchip,pins = <0x8 0x2 0x0 0x10b>;
				linux,phandle = <0x11b>;
				phandle = <0x11b>;
			};

			work-led {
				rockchip,pins = <0x8 0x1 0x0 0x10b>;
				linux,phandle = <0x11a>;
				phandle = <0x11a>;
			};
		};

		sdio-pwrseq {

			wifi-enable-h {
				rockchip,pins = <0x4 0x1c 0x0 0x10b>;
				linux,phandle = <0x11d>;
				phandle = <0x11d>;
			};
		};

		usb_host {

			host-vbus-drv {
				rockchip,pins = <0x0 0xe 0x0 0x10b>;
				linux,phandle = <0x121>;
				phandle = <0x121>;
			};

			usbhub-rst {
				rockchip,pins = <0x8 0x3 0x0 0x111>;
				linux,phandle = <0xc0>;
				phandle = <0xc0>;
			};
		};

		usb_otg {

			otg-vbus-drv {
				rockchip,pins = <0x0 0xc 0x0 0x10b>;
				linux,phandle = <0x123>;
				phandle = <0x123>;
			};
		};

		wireless-bluetooth {

			uart0-gpios {
				rockchip,pins = <0x4 0x13 0x0 0x10b>;
				linux,phandle = <0x126>;
				phandle = <0x126>;
			};
		};

		ir {

			ir-int {
				rockchip,pins = <0x7 0x0 0x0 0x10c>;
				linux,phandle = <0x117>;
				phandle = <0x117>;
			};
		};
	};

	rockchip-suspend {
		compatible = "rockchip,pm-rk3288";
		status = "disabled";
		rockchip,sleep-mode-config = <0x80207>;
		rockchip,wakeup-config = <0x8>;
		rockchip,pwm-regulator-config = <0x4>;
	};

	backlight {
		compatible = "pwm-backlight";
		brightness-levels = <0x3 0x4 0x5 0x6 0x7 0x8 0x9 0xa 0xb 0xc 0xd 0xe 0xf 0x10 0x11 0x12 0x13 0x14 0x15 0x16 0x17 0x18 0x19 0x1a 0x1b 0x1c 0x1d 0x1e 0x1f 0x20 0x21 0x22 0x23 0x24 0x25 0x26 0x27 0x28 0x29 0x2a 0x2b 0x2c 0x2d 0x2e 0x2f 0x30 0x31 0x32 0x33 0x34 0x35 0x36 0x37 0x38 0x39 0x3a 0x3b 0x3c 0x3d 0x3e 0x3f 0x40 0x41 0x42 0x43 0x44 0x45 0x46 0x47 0x48 0x49 0x4a 0x4b 0x4c 0x4d 0x4e 0x4f 0x50 0x51 0x52 0x53 0x54 0x55 0x56 0x57 0x58 0x59 0x5a 0x5b 0x5c 0x5d 0x5e 0x5f 0x60 0x61 0x62 0x63 0x64 0x65 0x66 0x67 0x68 0x69 0x6a 0x6b 0x6c 0x6d 0x6e 0x6f 0x70 0x71 0x72 0x73 0x74 0x75 0x76 0x77 0x78 0x79 0x7a 0x7b 0x7c 0x7d 0x7e 0x7f 0x80 0x81 0x82 0x83 0x84 0x85 0x86 0x87 0x88 0x89 0x8a 0x8b 0x8c 0x8d 0x8e 0x8f 0x90 0x91 0x92 0x93 0x94 0x95 0x96 0x97 0x98 0x99 0x9a 0x9b 0x9c 0x9d 0x9e 0x9f 0xa0 0xa1 0xa2 0xa3 0xa4 0xa5 0xa6 0xa7 0xa8 0xa9 0xaa 0xab 0xac 0xad 0xae 0xaf 0xb0 0xb1 0xb2 0xb3 0xb4 0xb5 0xb6 0xb7 0xb8 0xb9 0xba 0xbb 0xbc 0xbd 0xbe 0xbf 0xc0 0xc1 0xc2 0xc3 0xc4 0xc5 0xc6 0xc7 0xc8 0xc9 0xca 0xcb 0xcc 0xcd 0xce 0xcf 0xd0 0xd1 0xd2 0xd3 0xd4 0xd5 0xd6 0xd7 0xd8 0xd9 0xda 0xdb 0xdc 0xdd 0xde 0xdf 0xe0 0xe1 0xe2 0xe3 0xe4 0xe5 0xe6 0xe7 0xe8 0xe9 0xea 0xeb 0xec 0xed 0xee 0xef 0xf0 0xf1 0xf2 0xf3 0xf4 0xf5 0xf6 0xf7 0xf8 0xf9 0xfa 0xfb 0xfc 0xfd 0xfe 0xff>;
		default-brightness-level = <0xb4>;
		pwms = <0x113 0x0 0x61a8 0x0>;
		pwm-names = "backlight";
		power-supply = <0x8a>;
		linux,phandle = <0x114>;
		phandle = <0x114>;
	};

	edp-panel {
		compatible = "lg,lp079qx1-sp0v";
		power-supply = <0x8a>;
		backlight = <0x114>;
		enable-gpios = <0xe2 0xd 0x0>;

		ports {

			port {

				endpoint {
					remote-endpoint = <0x115>;
					linux,phandle = <0xff>;
					phandle = <0xff>;
				};
			};
		};
	};

	dovdd-1v8-regulator {
		compatible = "regulator-fixed";
		regulator-name = "dovdd_1v8";
		regulator-min-microvolt = <0x1b7740>;
		regulator-max-microvolt = <0x1b7740>;
		vin-supply = <0x116>;
		linux,phandle = <0xd9>;
		phandle = <0xd9>;
	};

	external-gmac-clock {
		compatible = "fixed-clock";
		#clock-cells = <0x0>;
		clock-frequency = <0x7735940>;
		clock-output-names = "ext_gmac";
		linux,phandle = <0xb7>;
		phandle = <0xb7>;
	};

	ir-receiver {
		compatible = "gpio-ir-receiver";
		pinctrl-names = "default";
		pinctrl-0 = <0x117>;
		gpios = <0xa1 0x0 0x1>;
	};

	gpio-keys {
		compatible = "gpio-keys";
		#address-cells = <0x1>;
		#size-cells = <0x0>;

		button@0 {
			gpio-key,wakeup = <0x1>;
			gpios = <0xe2 0x5 0x1>;
			label = "GPIO Power";
			linux,code = <0x74>;
			pinctrl-names = "default";
			pinctrl-0 = <0x118>;
		};
	};

	leds {
		compatible = "gpio-leds";

		work {
			gpios = <0x119 0x1 0x1>;
			label = "firefly:blue:user";
			linux,default-trigger = "rc-feedback";
			pinctrl-names = "default";
			pinctrl-0 = <0x11a>;
		};

		power {
			gpios = <0x119 0x2 0x1>;
			label = "firefly:green:power";
			linux,default-trigger = "default-on";
			pinctrl-names = "default";
			pinctrl-0 = <0x11b>;
		};
	};

	sdio-pwrseq {
		compatible = "mmc-pwrseq-simple";
		clocks = <0x11c>;
		clock-names = "ext_clock";
		pinctrl-names = "default";
		pinctrl-0 = <0x11d>;
		reset-gpios = <0xbd 0x1c 0x1>;
		linux,phandle = <0x85>;
		phandle = <0x85>;
	};

	sound {
		compatible = "simple-audio-card";
		simple-audio-card,name = "SPDIF";

		simple-audio-card,dai-link@1 {

			cpu {
				sound-dai = <0x11e>;
			};

			codec {
				sound-dai = <0x11f>;
			};
		};
	};

	spdif-out {
		compatible = "linux,spdif-dit";
		#sound-dai-cells = <0x0>;
		linux,phandle = <0x11f>;
		phandle = <0x11f>;
	};

	vsys-regulator {
		compatible = "regulator-fixed";
		regulator-name = "vcc_sys";
		regulator-min-microvolt = <0x4c4b40>;
		regulator-max-microvolt = <0x4c4b40>;
		regulator-always-on;
		regulator-boot-on;
		linux,phandle = <0x8a>;
		phandle = <0x8a>;
	};

	sdmmc-regulator {
		compatible = "regulator-fixed";
		gpio = <0xa1 0xb 0x1>;
		pinctrl-names = "default";
		pinctrl-0 = <0x120>;
		regulator-name = "vcc_sd";
		regulator-min-microvolt = <0x325aa0>;
		regulator-max-microvolt = <0x325aa0>;
		startup-delay-us = <0x186a0>;
		vin-supply = <0x90>;
		linux,phandle = <0x83>;
		phandle = <0x83>;
	};

	flash-regulator {
		compatible = "regulator-fixed";
		regulator-name = "vcc_flash";
		regulator-min-microvolt = <0x1b7740>;
		regulator-max-microvolt = <0x1b7740>;
		vin-supply = <0x90>;
		linux,phandle = <0x91>;
		phandle = <0x91>;
	};

	usb-regulator {
		compatible = "regulator-fixed";
		regulator-name = "vcc_5v";
		regulator-min-microvolt = <0x4c4b40>;
		regulator-max-microvolt = <0x4c4b40>;
		regulator-always-on;
		regulator-boot-on;
		vin-supply = <0x8a>;
		linux,phandle = <0x122>;
		phandle = <0x122>;
	};

	usb-host-regulator {
		compatible = "regulator-fixed";
		enable-active-high;
		gpio = <0xe2 0xe 0x0>;
		pinctrl-names = "default";
		pinctrl-0 = <0x121>;
		regulator-name = "vcc_host_5v";
		regulator-min-microvolt = <0x4c4b40>;
		regulator-max-microvolt = <0x4c4b40>;
		regulator-always-on;
		vin-supply = <0x122>;
	};

	usb-otg-regulator {
		compatible = "regulator-fixed";
		enable-active-high;
		gpio = <0xe2 0xc 0x0>;
		pinctrl-names = "default";
		pinctrl-0 = <0x123>;
		regulator-name = "vcc_otg_5v";
		regulator-min-microvolt = <0x4c4b40>;
		regulator-max-microvolt = <0x4c4b40>;
		regulator-always-on;
		vin-supply = <0x122>;
	};

	vcc28-dvp-regulator {
		compatible = "regulator-fixed";
		enable-active-high;
		gpio = <0xe2 0xb 0x0>;
		pinctrl-names = "default";
		pinctrl-0 = <0x124>;
		regulator-name = "vcc28_dvp";
		regulator-min-microvolt = <0x2ab980>;
		regulator-max-microvolt = <0x2ab980>;
		regulator-always-on;
		vin-supply = <0x90>;
		linux,phandle = <0x116>;
		phandle = <0x116>;
	};

	wireless-bluetooth {
		compatible = "bluetooth-platdata";
		uart_rts_gpios = <0xbd 0x13 0x1>;
		pinctrl-names = "default", "rts_gpio";
		pinctrl-0 = <0x125>;
		pinctrl-1 = <0x126>;
		BT,reset_gpio = <0xbd 0x1d 0x0>;
		BT,wake_gpio = <0xbd 0x1a 0x0>;
		BT,wake_host_irq = <0xbd 0x1f 0x0>;
		status = "okay";
	};

	wireless-wlan {
		compatible = "wlan-platdata";
		rockchip,grf = <0xb6>;
		wifi_chip_type = "ap6335";
		sdio_vref = <0x708>;
		WIFI,host_wake_irq = <0xbd 0x1e 0x0>;
		status = "okay";
	};

	rk3288_cif_sensor {
		compatible = "rockchip,sensor";
		status = "okay";

		ov5640_for_test {
			is_front = <0x0>;
			power = <0xe2 0xb 0x0>;
			rockchip,powerdown = <0x127 0x47 0x0>;
			pwdn_active = <0x1>;
			pwr_active = <0x1>;
			mir = <0x0>;
			flash_attach = <0x0>;
			flash_active = <0x0>;
			resolution = <0x100000>;
			powerup_sequence = <0x7654>;
			orientation = <0x0>;
			i2c_add = <0x60>;
			i2c_rata = <0x186a0>;
			i2c_chl = <0x3>;
			cif_chl = <0x0>;
			mclk_rate = <0x18>;
		};
	};
};
